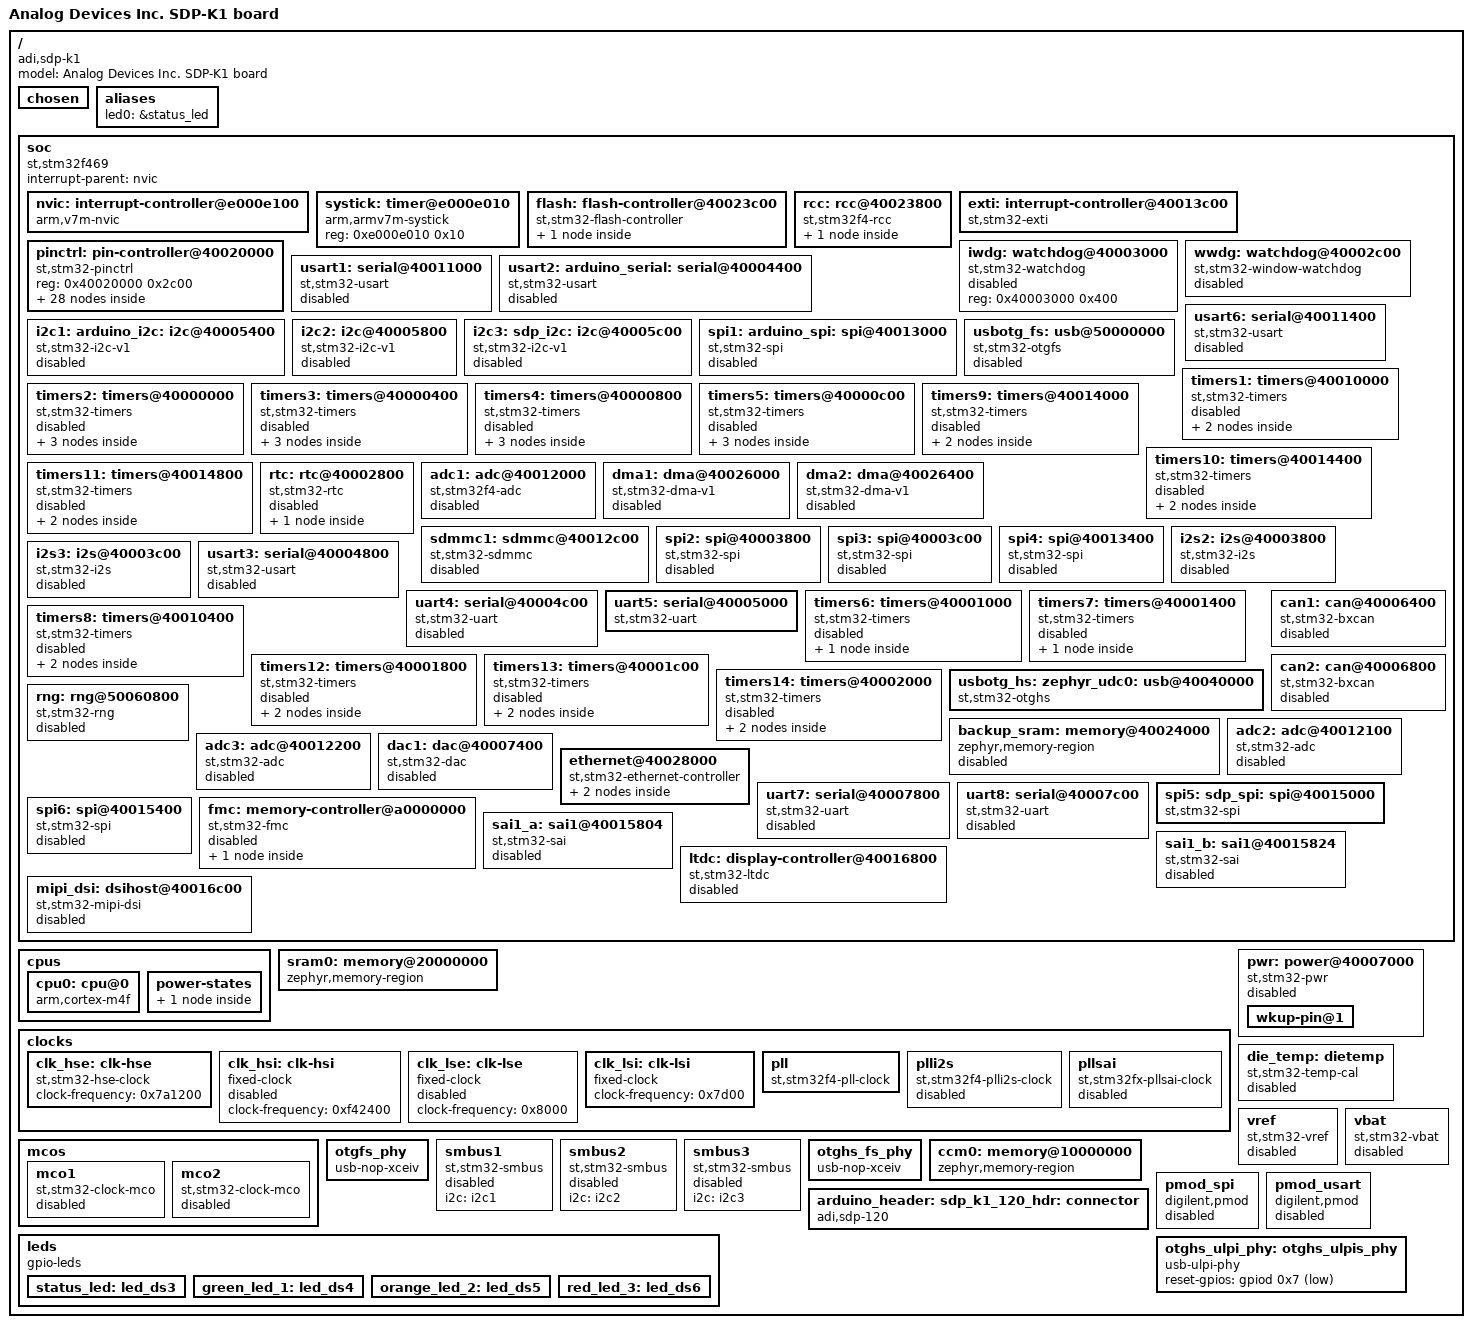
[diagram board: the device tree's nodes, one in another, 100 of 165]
/dts-v1/;

/* node '/' defined in zephyr/dts/common/skeleton.dtsi:9 */
/ {
	#address-cells = < 0x1 >;                   /* in zephyr/dts/common/skeleton.dtsi:10 */
	#size-cells = < 0x1 >;                      /* in zephyr/dts/common/skeleton.dtsi:11 */
	model = "Analog Devices Inc. SDP-K1 board"; /* in zephyr/boards/adi/sdp_k1/adi_sdp_k1.dts:14 */
	compatible = "adi,sdp-k1";                  /* in zephyr/boards/adi/sdp_k1/adi_sdp_k1.dts:15 */

	/* node '/chosen' defined in zephyr/dts/common/skeleton.dtsi:13 */
	chosen {
		zephyr,flash-controller = &flash;  /* in zephyr/dts/arm/st/f4/stm32f4.dtsi:27 */
		zephyr,cortex-m-idle-timer = &rtc; /* in zephyr/dts/arm/st/f4/stm32f4.dtsi:28 */
		zephyr,entropy = &rng;             /* in zephyr/dts/arm/st/f4/stm32f405.dtsi:13 */
		zephyr,console = &uart5;           /* in zephyr/boards/adi/sdp_k1/adi_sdp_k1.dts:18 */
		zephyr,shell-uart = &uart5;        /* in zephyr/boards/adi/sdp_k1/adi_sdp_k1.dts:19 */
		zephyr,sram = &sram0;              /* in zephyr/boards/adi/sdp_k1/adi_sdp_k1.dts:20 */
		zephyr,flash = &flash0;            /* in zephyr/boards/adi/sdp_k1/adi_sdp_k1.dts:21 */
		zephyr,ccm = &ccm0;                /* in zephyr/boards/adi/sdp_k1/adi_sdp_k1.dts:22 */
	};

	/* node '/aliases' defined in zephyr/dts/common/skeleton.dtsi:15 */
	aliases {
		led0 = &status_led; /* in zephyr/boards/adi/sdp_k1/adi_sdp_k1.dts:56 */
	};

	/* node '/soc' defined in zephyr/dts/arm/armv7-m.dtsi:6 */
	soc {
		#address-cells = < 0x1 >;     /* in zephyr/dts/arm/armv7-m.dtsi:7 */
		#size-cells = < 0x1 >;        /* in zephyr/dts/arm/armv7-m.dtsi:8 */
		interrupt-parent = < &nvic >; /* in zephyr/dts/arm/armv7-m.dtsi:10 */
		ranges;                       /* in zephyr/dts/arm/armv7-m.dtsi:11 */
		compatible = "st,stm32f469",
		             "st,stm32f4",
		             "simple-bus";    /* in zephyr/dts/arm/st/f4/stm32f469.dtsi:12 */

		/* node '/soc/interrupt-controller@e000e100' defined in zephyr/dts/arm/armv7-m.dtsi:13 */
		nvic: interrupt-controller@e000e100 {
			#address-cells = < 0x1 >;            /* in zephyr/dts/arm/armv7-m.dtsi:14 */
			compatible = "arm,v7m-nvic";         /* in zephyr/dts/arm/armv7-m.dtsi:15 */
			reg = < 0xe000e100 0xc00 >;          /* in zephyr/dts/arm/armv7-m.dtsi:16 */
			interrupt-controller;                /* in zephyr/dts/arm/armv7-m.dtsi:17 */
			#interrupt-cells = < 0x2 >;          /* in zephyr/dts/arm/armv7-m.dtsi:18 */
			arm,num-irq-priority-bits = < 0x4 >; /* in zephyr/dts/arm/st/f4/stm32f4.dtsi:676 */
			phandle = < 0x1 >;                   /* in zephyr/dts/arm/armv7-m.dtsi:10 */
		};

		/* node '/soc/timer@e000e010' defined in zephyr/dts/arm/armv7-m.dtsi:21 */
		systick: timer@e000e010 {
			compatible = "arm,armv7m-systick"; /* in zephyr/dts/arm/armv7-m.dtsi:22 */
			reg = < 0xe000e010 0x10 >;         /* in zephyr/dts/arm/armv7-m.dtsi:23 */
		};

		/* node '/soc/flash-controller@40023c00' defined in zephyr/dts/arm/st/f4/stm32f4.dtsi:111 */
		flash: flash-controller@40023c00 {
			compatible = "st,stm32-flash-controller",
			             "st,stm32f4-flash-controller"; /* in zephyr/dts/arm/st/f4/stm32f4.dtsi:112 */
			reg = < 0x40023c00 0x400 >;                 /* in zephyr/dts/arm/st/f4/stm32f4.dtsi:113 */
			interrupts = < 0x4 0x0 >;                   /* in zephyr/dts/arm/st/f4/stm32f4.dtsi:114 */
			#address-cells = < 0x1 >;                   /* in zephyr/dts/arm/st/f4/stm32f4.dtsi:116 */
			#size-cells = < 0x1 >;                      /* in zephyr/dts/arm/st/f4/stm32f4.dtsi:117 */

			/* node '/soc/flash-controller@40023c00/flash@8000000' defined in zephyr/dts/arm/st/f4/stm32f4.dtsi:119 */
			flash0: flash@8000000 {
				compatible = "st,stm32f4-nv-flash",
				             "st,stm32-nv-flash",
				             "soc-nv-flash";        /* in zephyr/dts/arm/st/f4/stm32f4.dtsi:120 */
				write-block-size = < 0x1 >;         /* in zephyr/dts/arm/st/f4/stm32f4.dtsi:123 */
				max-erase-time = < 0xfa0 >;         /* in zephyr/dts/arm/st/f4/stm32f4.dtsi:125 */
				reg = < 0x8000000 0x200000 >;       /* in zephyr/dts/arm/st/f4/stm32f469Xi.dtsi:23 */
			};
		};

		/* node '/soc/rcc@40023800' defined in zephyr/dts/arm/st/f4/stm32f4.dtsi:129 */
		rcc: rcc@40023800 {
			#clock-cells = < 0x2 >;          /* in zephyr/dts/arm/st/f4/stm32f4.dtsi:131 */
			reg = < 0x40023800 0x400 >;      /* in zephyr/dts/arm/st/f4/stm32f4.dtsi:132 */
			compatible = "st,stm32f4-rcc";   /* in zephyr/dts/arm/st/f4/stm32f427.dtsi:25 */
			clocks = < &pll >;               /* in zephyr/boards/adi/sdp_k1/adi_sdp_k1.dts:79 */
			clock-frequency = < 0xa037a00 >; /* in zephyr/boards/adi/sdp_k1/adi_sdp_k1.dts:80 */
			ahb-prescaler = < 0x1 >;         /* in zephyr/boards/adi/sdp_k1/adi_sdp_k1.dts:81 */
			apb1-prescaler = < 0x4 >;        /* in zephyr/boards/adi/sdp_k1/adi_sdp_k1.dts:82 */
			apb2-prescaler = < 0x2 >;        /* in zephyr/boards/adi/sdp_k1/adi_sdp_k1.dts:83 */
			phandle = < 0x3 >;               /* in zephyr/dts/arm/st/f4/stm32f4.dtsi:146 */

			/* node '/soc/rcc@40023800/reset-controller' defined in zephyr/dts/arm/st/f4/stm32f4.dtsi:134 */
			rctl: reset-controller {
				compatible = "st,stm32-rcc-rctl"; /* in zephyr/dts/arm/st/f4/stm32f4.dtsi:135 */
				#reset-cells = < 0x1 >;           /* in zephyr/dts/arm/st/f4/stm32f4.dtsi:136 */
				phandle = < 0x4 >;                /* in zephyr/dts/arm/st/f4/stm32f4.dtsi:245 */
			};
		};

		/* node '/soc/interrupt-controller@40013c00' defined in zephyr/dts/arm/st/f4/stm32f4.dtsi:140 */
		exti: interrupt-controller@40013c00 {
			compatible = "st,stm32-exti";  /* in zephyr/dts/arm/st/f4/stm32f4.dtsi:141 */
			interrupt-controller;          /* in zephyr/dts/arm/st/f4/stm32f4.dtsi:142 */
			#interrupt-cells = < 0x1 >;    /* in zephyr/dts/arm/st/f4/stm32f4.dtsi:143 */
			#address-cells = < 0x0 >;      /* in zephyr/dts/arm/st/f4/stm32f4.dtsi:144 */
			reg = < 0x40013c00 0x400 >;    /* in zephyr/dts/arm/st/f4/stm32f4.dtsi:145 */
			clocks = < &rcc 0x44 0x4000 >; /* in zephyr/dts/arm/st/f4/stm32f4.dtsi:146 */
			num-lines = < 0x20 >;          /* in zephyr/dts/arm/st/f4/stm32f4.dtsi:147 */
			interrupts = < 0x6 0x0 >,
			             < 0x7 0x0 >,
			             < 0x8 0x0 >,
			             < 0x9 0x0 >,
			             < 0xa 0x0 >,
			             < 0x17 0x0 >,
			             < 0x28 0x0 >;     /* in zephyr/dts/arm/st/f4/stm32f4.dtsi:148 */
			interrupt-names = "line0",
			                  "line1",
			                  "line2",
			                  "line3",
			                  "line4",
			                  "line5-9",
			                  "line10-15"; /* in zephyr/dts/arm/st/f4/stm32f4.dtsi:150 */
			line-ranges = < 0x0 0x1 >,
			              < 0x1 0x1 >,
			              < 0x2 0x1 >,
			              < 0x3 0x1 >,
			              < 0x4 0x1 >,
			              < 0x5 0x5 >,
			              < 0xa 0x6 >;     /* in zephyr/dts/arm/st/f4/stm32f4.dtsi:152 */
		};

		/* node '/soc/pin-controller@40020000' defined in zephyr/dts/arm/st/f4/stm32f4.dtsi:156 */
		pinctrl: pin-controller@40020000 {
			compatible = "st,stm32-pinctrl"; /* in zephyr/dts/arm/st/f4/stm32f4.dtsi:157 */
			#address-cells = < 0x1 >;        /* in zephyr/dts/arm/st/f4/stm32f4.dtsi:158 */
			#size-cells = < 0x1 >;           /* in zephyr/dts/arm/st/f4/stm32f4.dtsi:159 */
			reg = < 0x40020000 0x2c00 >;     /* in zephyr/dts/arm/st/f4/stm32f427.dtsi:29 */

			/* node '/soc/pin-controller@40020000/gpio@40020000' defined in zephyr/dts/arm/st/f4/stm32f4.dtsi:162 */
			gpioa: gpio@40020000 {
				compatible = "st,stm32-gpio"; /* in zephyr/dts/arm/st/f4/stm32f4.dtsi:163 */
				gpio-controller;              /* in zephyr/dts/arm/st/f4/stm32f4.dtsi:164 */
				#gpio-cells = < 0x2 >;        /* in zephyr/dts/arm/st/f4/stm32f4.dtsi:165 */
				reg = < 0x40020000 0x400 >;   /* in zephyr/dts/arm/st/f4/stm32f4.dtsi:166 */
				clocks = < &rcc 0x30 0x1 >;   /* in zephyr/dts/arm/st/f4/stm32f4.dtsi:167 */
				phandle = < 0x1d >;           /* in zephyr/dts/arm/st/f4/stm32f4.dtsi:615 */
			};

			/* node '/soc/pin-controller@40020000/gpio@40020400' defined in zephyr/dts/arm/st/f4/stm32f4.dtsi:170 */
			gpiob: gpio@40020400 {
				compatible = "st,stm32-gpio"; /* in zephyr/dts/arm/st/f4/stm32f4.dtsi:171 */
				gpio-controller;              /* in zephyr/dts/arm/st/f4/stm32f4.dtsi:172 */
				#gpio-cells = < 0x2 >;        /* in zephyr/dts/arm/st/f4/stm32f4.dtsi:173 */
				reg = < 0x40020400 0x400 >;   /* in zephyr/dts/arm/st/f4/stm32f4.dtsi:174 */
				clocks = < &rcc 0x30 0x2 >;   /* in zephyr/dts/arm/st/f4/stm32f4.dtsi:175 */
				phandle = < 0x26 >;           /* in zephyr/boards/adi/sdp_k1/adi_sdp_120pin_connector.dtsi:16 */
			};

			/* node '/soc/pin-controller@40020000/gpio@40020800' defined in zephyr/dts/arm/st/f4/stm32f4.dtsi:178 */
			gpioc: gpio@40020800 {
				compatible = "st,stm32-gpio"; /* in zephyr/dts/arm/st/f4/stm32f4.dtsi:179 */
				gpio-controller;              /* in zephyr/dts/arm/st/f4/stm32f4.dtsi:180 */
				#gpio-cells = < 0x2 >;        /* in zephyr/dts/arm/st/f4/stm32f4.dtsi:181 */
				reg = < 0x40020800 0x400 >;   /* in zephyr/dts/arm/st/f4/stm32f4.dtsi:182 */
				clocks = < &rcc 0x30 0x4 >;   /* in zephyr/dts/arm/st/f4/stm32f4.dtsi:183 */
				phandle = < 0x24 >;           /* in zephyr/boards/adi/sdp_k1/adi_sdp_120pin_connector.dtsi:16 */
			};

			/* node '/soc/pin-controller@40020000/gpio@40020c00' defined in zephyr/dts/arm/st/f4/stm32f4.dtsi:186 */
			gpiod: gpio@40020c00 {
				compatible = "st,stm32-gpio"; /* in zephyr/dts/arm/st/f4/stm32f4.dtsi:187 */
				gpio-controller;              /* in zephyr/dts/arm/st/f4/stm32f4.dtsi:188 */
				#gpio-cells = < 0x2 >;        /* in zephyr/dts/arm/st/f4/stm32f4.dtsi:189 */
				reg = < 0x40020c00 0x400 >;   /* in zephyr/dts/arm/st/f4/stm32f4.dtsi:190 */
				clocks = < &rcc 0x30 0x8 >;   /* in zephyr/dts/arm/st/f4/stm32f4.dtsi:191 */
				phandle = < 0x23 >;           /* in zephyr/boards/adi/sdp_k1/adi_sdp_120pin_connector.dtsi:16 */
			};

			/* node '/soc/pin-controller@40020000/gpio@40021000' defined in zephyr/dts/arm/st/f4/stm32f4.dtsi:194 */
			gpioe: gpio@40021000 {
				compatible = "st,stm32-gpio"; /* in zephyr/dts/arm/st/f4/stm32f4.dtsi:195 */
				gpio-controller;              /* in zephyr/dts/arm/st/f4/stm32f4.dtsi:196 */
				#gpio-cells = < 0x2 >;        /* in zephyr/dts/arm/st/f4/stm32f4.dtsi:197 */
				reg = < 0x40021000 0x400 >;   /* in zephyr/dts/arm/st/f4/stm32f4.dtsi:198 */
				clocks = < &rcc 0x30 0x10 >;  /* in zephyr/dts/arm/st/f4/stm32f4.dtsi:199 */
				phandle = < 0x27 >;           /* in zephyr/boards/adi/sdp_k1/adi_sdp_120pin_connector.dtsi:16 */
			};

			/* node '/soc/pin-controller@40020000/gpio@40021400' defined in zephyr/dts/arm/st/f4/stm32f4.dtsi:202 */
			gpiof: gpio@40021400 {
				compatible = "st,stm32-gpio"; /* in zephyr/dts/arm/st/f4/stm32f405.dtsi:27 */
				gpio-controller;              /* in zephyr/dts/arm/st/f4/stm32f405.dtsi:28 */
				#gpio-cells = < 0x2 >;        /* in zephyr/dts/arm/st/f4/stm32f405.dtsi:29 */
				reg = < 0x40021400 0x400 >;   /* in zephyr/dts/arm/st/f4/stm32f405.dtsi:30 */
				clocks = < &rcc 0x30 0x20 >;  /* in zephyr/dts/arm/st/f4/stm32f405.dtsi:31 */
				phandle = < 0x22 >;           /* in zephyr/boards/adi/sdp_k1/adi_sdp_120pin_connector.dtsi:16 */
			};

			/* node '/soc/pin-controller@40020000/gpio@40021800' defined in zephyr/dts/arm/st/f4/stm32f4.dtsi:210 */
			gpiog: gpio@40021800 {
				compatible = "st,stm32-gpio"; /* in zephyr/dts/arm/st/f4/stm32f405.dtsi:35 */
				gpio-controller;              /* in zephyr/dts/arm/st/f4/stm32f405.dtsi:36 */
				#gpio-cells = < 0x2 >;        /* in zephyr/dts/arm/st/f4/stm32f405.dtsi:37 */
				reg = < 0x40021800 0x400 >;   /* in zephyr/dts/arm/st/f4/stm32f405.dtsi:38 */
				clocks = < &rcc 0x30 0x40 >;  /* in zephyr/dts/arm/st/f4/stm32f405.dtsi:39 */
				phandle = < 0x29 >;           /* in zephyr/boards/adi/sdp_k1/adi_sdp_120pin_connector.dtsi:16 */
			};

			/* node '/soc/pin-controller@40020000/gpio@40021c00' defined in zephyr/dts/arm/st/f4/stm32f4.dtsi:218 */
			gpioh: gpio@40021c00 {
				compatible = "st,stm32-gpio"; /* in zephyr/dts/arm/st/f4/stm32f4.dtsi:219 */
				gpio-controller;              /* in zephyr/dts/arm/st/f4/stm32f4.dtsi:220 */
				#gpio-cells = < 0x2 >;        /* in zephyr/dts/arm/st/f4/stm32f4.dtsi:221 */
				reg = < 0x40021c00 0x400 >;   /* in zephyr/dts/arm/st/f4/stm32f4.dtsi:222 */
				clocks = < &rcc 0x30 0x80 >;  /* in zephyr/dts/arm/st/f4/stm32f4.dtsi:223 */
				phandle = < 0x28 >;           /* in zephyr/boards/adi/sdp_k1/adi_sdp_120pin_connector.dtsi:16 */
			};

			/* node '/soc/pin-controller@40020000/gpio@40022000' defined in zephyr/dts/arm/st/f4/stm32f405.dtsi:42 */
			gpioi: gpio@40022000 {
				compatible = "st,stm32-gpio"; /* in zephyr/dts/arm/st/f4/stm32f405.dtsi:43 */
				gpio-controller;              /* in zephyr/dts/arm/st/f4/stm32f405.dtsi:44 */
				#gpio-cells = < 0x2 >;        /* in zephyr/dts/arm/st/f4/stm32f405.dtsi:45 */
				reg = < 0x40022000 0x400 >;   /* in zephyr/dts/arm/st/f4/stm32f405.dtsi:46 */
				clocks = < &rcc 0x30 0x100 >; /* in zephyr/dts/arm/st/f4/stm32f405.dtsi:47 */
			};

			/* node '/soc/pin-controller@40020000/gpio@40022400' defined in zephyr/dts/arm/st/f4/stm32f427.dtsi:31 */
			gpioj: gpio@40022400 {
				compatible = "st,stm32-gpio"; /* in zephyr/dts/arm/st/f4/stm32f427.dtsi:32 */
				gpio-controller;              /* in zephyr/dts/arm/st/f4/stm32f427.dtsi:33 */
				#gpio-cells = < 0x2 >;        /* in zephyr/dts/arm/st/f4/stm32f427.dtsi:34 */
				reg = < 0x40022400 0x400 >;   /* in zephyr/dts/arm/st/f4/stm32f427.dtsi:35 */
				clocks = < &rcc 0x30 0x200 >; /* in zephyr/dts/arm/st/f4/stm32f427.dtsi:36 */
				phandle = < 0x25 >;           /* in zephyr/boards/adi/sdp_k1/adi_sdp_120pin_connector.dtsi:16 */
			};

			/* node '/soc/pin-controller@40020000/gpio@40022800' defined in zephyr/dts/arm/st/f4/stm32f427.dtsi:39 */
			gpiok: gpio@40022800 {
				compatible = "st,stm32-gpio"; /* in zephyr/dts/arm/st/f4/stm32f427.dtsi:40 */
				gpio-controller;              /* in zephyr/dts/arm/st/f4/stm32f427.dtsi:41 */
				#gpio-cells = < 0x2 >;        /* in zephyr/dts/arm/st/f4/stm32f427.dtsi:42 */
				reg = < 0x40022800 0x400 >;   /* in zephyr/dts/arm/st/f4/stm32f427.dtsi:43 */
				clocks = < &rcc 0x30 0x400 >; /* in zephyr/dts/arm/st/f4/stm32f427.dtsi:44 */
				phandle = < 0x2a >;           /* in zephyr/boards/adi/sdp_k1/adi_sdp_k1.dts:29 */
			};

			/* node '/soc/pin-controller@40020000/spi5_miso_pf8' defined in modules/hal/stm32/dts/st/f4/stm32f469nihx-pinctrl.dtsi:2758 */
			spi5_miso_pf8: spi5_miso_pf8 {
				pinmux = < 0xb05 >; /* in modules/hal/stm32/dts/st/f4/stm32f469nihx-pinctrl.dtsi:2759 */
				bias-pull-down;     /* in modules/hal/stm32/dts/st/f4/stm32f469nihx-pinctrl.dtsi:2760 */
				phandle = < 0x17 >; /* in zephyr/boards/adi/sdp_k1/adi_sdp_120pin_connector.dtsi:106 */
			};

			/* node '/soc/pin-controller@40020000/spi5_mosi_pf9' defined in modules/hal/stm32/dts/st/f4/stm32f469nihx-pinctrl.dtsi:2830 */
			spi5_mosi_pf9: spi5_mosi_pf9 {
				pinmux = < 0xb25 >; /* in modules/hal/stm32/dts/st/f4/stm32f469nihx-pinctrl.dtsi:2831 */
				bias-pull-down;     /* in modules/hal/stm32/dts/st/f4/stm32f469nihx-pinctrl.dtsi:2832 */
				phandle = < 0x18 >; /* in zephyr/boards/adi/sdp_k1/adi_sdp_120pin_connector.dtsi:106 */
			};

			/* node '/soc/pin-controller@40020000/spi5_sck_ph6' defined in modules/hal/stm32/dts/st/f4/stm32f469nihx-pinctrl.dtsi:2981 */
			spi5_sck_ph6: spi5_sck_ph6 {
				pinmux = < 0xec5 >;            /* in modules/hal/stm32/dts/st/f4/stm32f469nihx-pinctrl.dtsi:2982 */
				bias-pull-down;                /* in modules/hal/stm32/dts/st/f4/stm32f469nihx-pinctrl.dtsi:2983 */
				slew-rate = "very-high-speed"; /* in modules/hal/stm32/dts/st/f4/stm32f469nihx-pinctrl.dtsi:2984 */
				phandle = < 0x16 >;            /* in zephyr/boards/adi/sdp_k1/adi_sdp_120pin_connector.dtsi:106 */
			};

			/* node '/soc/pin-controller@40020000/uart5_rx_pd2' defined in modules/hal/stm32/dts/st/f4/stm32f469nihx-pinctrl.dtsi:3469 */
			uart5_rx_pd2: uart5_rx_pd2 {
				pinmux = < 0x648 >; /* in modules/hal/stm32/dts/st/f4/stm32f469nihx-pinctrl.dtsi:3470 */
				phandle = < 0x8 >;  /* in zephyr/boards/adi/sdp_k1/adi_sdp_k1.dts:87 */
			};

			/* node '/soc/pin-controller@40020000/uart5_tx_pc12' defined in modules/hal/stm32/dts/st/f4/stm32f469nihx-pinctrl.dtsi:3540 */
			uart5_tx_pc12: uart5_tx_pc12 {
				pinmux = < 0x588 >; /* in modules/hal/stm32/dts/st/f4/stm32f469nihx-pinctrl.dtsi:3541 */
				bias-pull-up;       /* in modules/hal/stm32/dts/st/f4/stm32f469nihx-pinctrl.dtsi:3542 */
				phandle = < 0x7 >;  /* in zephyr/boards/adi/sdp_k1/adi_sdp_k1.dts:87 */
			};

			/* node '/soc/pin-controller@40020000/usb_otg_hs_ulpi_d0_pa3' defined in modules/hal/stm32/dts/st/f4/stm32f469nihx-pinctrl.dtsi:3616 */
			usb_otg_hs_ulpi_d0_pa3: usb_otg_hs_ulpi_d0_pa3 {
				pinmux = < 0x6a >;        /* in modules/hal/stm32/dts/st/f4/stm32f469nihx-pinctrl.dtsi:3617 */
				slew-rate = "high-speed"; /* in modules/hal/stm32/dts/st/f4/stm32f469nihx-pinctrl.dtsi:3618 */
				phandle = < 0xa >;        /* in zephyr/boards/adi/sdp_k1/adi_sdp_k1.dts:94 */
			};

			/* node '/soc/pin-controller@40020000/usb_otg_hs_ulpi_ck_pa5' defined in modules/hal/stm32/dts/st/f4/stm32f469nihx-pinctrl.dtsi:3621 */
			usb_otg_hs_ulpi_ck_pa5: usb_otg_hs_ulpi_ck_pa5 {
				pinmux = < 0xaa >;        /* in modules/hal/stm32/dts/st/f4/stm32f469nihx-pinctrl.dtsi:3622 */
				slew-rate = "high-speed"; /* in modules/hal/stm32/dts/st/f4/stm32f469nihx-pinctrl.dtsi:3623 */
				phandle = < 0x9 >;        /* in zephyr/boards/adi/sdp_k1/adi_sdp_k1.dts:94 */
			};

			/* node '/soc/pin-controller@40020000/usb_otg_hs_ulpi_d1_pb0' defined in modules/hal/stm32/dts/st/f4/stm32f469nihx-pinctrl.dtsi:3626 */
			usb_otg_hs_ulpi_d1_pb0: usb_otg_hs_ulpi_d1_pb0 {
				pinmux = < 0x20a >;       /* in modules/hal/stm32/dts/st/f4/stm32f469nihx-pinctrl.dtsi:3627 */
				slew-rate = "high-speed"; /* in modules/hal/stm32/dts/st/f4/stm32f469nihx-pinctrl.dtsi:3628 */
				phandle = < 0xb >;        /* in zephyr/boards/adi/sdp_k1/adi_sdp_k1.dts:94 */
			};

			/* node '/soc/pin-controller@40020000/usb_otg_hs_ulpi_d2_pb1' defined in modules/hal/stm32/dts/st/f4/stm32f469nihx-pinctrl.dtsi:3631 */
			usb_otg_hs_ulpi_d2_pb1: usb_otg_hs_ulpi_d2_pb1 {
				pinmux = < 0x22a >;       /* in modules/hal/stm32/dts/st/f4/stm32f469nihx-pinctrl.dtsi:3632 */
				slew-rate = "high-speed"; /* in modules/hal/stm32/dts/st/f4/stm32f469nihx-pinctrl.dtsi:3633 */
				phandle = < 0xc >;        /* in zephyr/boards/adi/sdp_k1/adi_sdp_k1.dts:94 */
			};

			/* node '/soc/pin-controller@40020000/usb_otg_hs_ulpi_d7_pb5' defined in modules/hal/stm32/dts/st/f4/stm32f469nihx-pinctrl.dtsi:3636 */
			usb_otg_hs_ulpi_d7_pb5: usb_otg_hs_ulpi_d7_pb5 {
				pinmux = < 0x2aa >;       /* in modules/hal/stm32/dts/st/f4/stm32f469nihx-pinctrl.dtsi:3637 */
				slew-rate = "high-speed"; /* in modules/hal/stm32/dts/st/f4/stm32f469nihx-pinctrl.dtsi:3638 */
				phandle = < 0x11 >;       /* in zephyr/boards/adi/sdp_k1/adi_sdp_k1.dts:94 */
			};

			/* node '/soc/pin-controller@40020000/usb_otg_hs_ulpi_d3_pb10' defined in modules/hal/stm32/dts/st/f4/stm32f469nihx-pinctrl.dtsi:3641 */
			usb_otg_hs_ulpi_d3_pb10: usb_otg_hs_ulpi_d3_pb10 {
				pinmux = < 0x34a >;       /* in modules/hal/stm32/dts/st/f4/stm32f469nihx-pinctrl.dtsi:3642 */
				slew-rate = "high-speed"; /* in modules/hal/stm32/dts/st/f4/stm32f469nihx-pinctrl.dtsi:3643 */
				phandle = < 0xd >;        /* in zephyr/boards/adi/sdp_k1/adi_sdp_k1.dts:94 */
			};

			/* node '/soc/pin-controller@40020000/usb_otg_hs_ulpi_d4_pb11' defined in modules/hal/stm32/dts/st/f4/stm32f469nihx-pinctrl.dtsi:3646 */
			usb_otg_hs_ulpi_d4_pb11: usb_otg_hs_ulpi_d4_pb11 {
				pinmux = < 0x36a >;       /* in modules/hal/stm32/dts/st/f4/stm32f469nihx-pinctrl.dtsi:3647 */
				slew-rate = "high-speed"; /* in modules/hal/stm32/dts/st/f4/stm32f469nihx-pinctrl.dtsi:3648 */
				phandle = < 0xe >;        /* in zephyr/boards/adi/sdp_k1/adi_sdp_k1.dts:94 */
			};

			/* node '/soc/pin-controller@40020000/usb_otg_hs_ulpi_d5_pb12' defined in modules/hal/stm32/dts/st/f4/stm32f469nihx-pinctrl.dtsi:3651 */
			usb_otg_hs_ulpi_d5_pb12: usb_otg_hs_ulpi_d5_pb12 {
				pinmux = < 0x38a >;       /* in modules/hal/stm32/dts/st/f4/stm32f469nihx-pinctrl.dtsi:3652 */
				slew-rate = "high-speed"; /* in modules/hal/stm32/dts/st/f4/stm32f469nihx-pinctrl.dtsi:3653 */
				phandle = < 0xf >;        /* in zephyr/boards/adi/sdp_k1/adi_sdp_k1.dts:94 */
			};

			/* node '/soc/pin-controller@40020000/usb_otg_hs_ulpi_d6_pb13' defined in modules/hal/stm32/dts/st/f4/stm32f469nihx-pinctrl.dtsi:3656 */
			usb_otg_hs_ulpi_d6_pb13: usb_otg_hs_ulpi_d6_pb13 {
				pinmux = < 0x3aa >;       /* in modules/hal/stm32/dts/st/f4/stm32f469nihx-pinctrl.dtsi:3657 */
				slew-rate = "high-speed"; /* in modules/hal/stm32/dts/st/f4/stm32f469nihx-pinctrl.dtsi:3658 */
				phandle = < 0x10 >;       /* in zephyr/boards/adi/sdp_k1/adi_sdp_k1.dts:94 */
			};

			/* node '/soc/pin-controller@40020000/usb_otg_hs_ulpi_stp_pc0' defined in modules/hal/stm32/dts/st/f4/stm32f469nihx-pinctrl.dtsi:3661 */
			usb_otg_hs_ulpi_stp_pc0: usb_otg_hs_ulpi_stp_pc0 {
				pinmux = < 0x40a >;       /* in modules/hal/stm32/dts/st/f4/stm32f469nihx-pinctrl.dtsi:3662 */
				slew-rate = "high-speed"; /* in modules/hal/stm32/dts/st/f4/stm32f469nihx-pinctrl.dtsi:3663 */
				phandle = < 0x12 >;       /* in zephyr/boards/adi/sdp_k1/adi_sdp_k1.dts:94 */
			};

			/* node '/soc/pin-controller@40020000/usb_otg_hs_ulpi_dir_pc2' defined in modules/hal/stm32/dts/st/f4/stm32f469nihx-pinctrl.dtsi:3666 */
			usb_otg_hs_ulpi_dir_pc2: usb_otg_hs_ulpi_dir_pc2 {
				pinmux = < 0x44a >;       /* in modules/hal/stm32/dts/st/f4/stm32f469nihx-pinctrl.dtsi:3667 */
				slew-rate = "high-speed"; /* in modules/hal/stm32/dts/st/f4/stm32f469nihx-pinctrl.dtsi:3668 */
				phandle = < 0x13 >;       /* in zephyr/boards/adi/sdp_k1/adi_sdp_k1.dts:94 */
			};

			/* node '/soc/pin-controller@40020000/usb_otg_hs_ulpi_nxt_pc3' defined in modules/hal/stm32/dts/st/f4/stm32f469nihx-pinctrl.dtsi:3671 */
			usb_otg_hs_ulpi_nxt_pc3: usb_otg_hs_ulpi_nxt_pc3 {
				pinmux = < 0x46a >;       /* in modules/hal/stm32/dts/st/f4/stm32f469nihx-pinctrl.dtsi:3672 */
				slew-rate = "high-speed"; /* in modules/hal/stm32/dts/st/f4/stm32f469nihx-pinctrl.dtsi:3673 */
				phandle = < 0x14 >;       /* in zephyr/boards/adi/sdp_k1/adi_sdp_k1.dts:94 */
			};
		};

		/* node '/soc/watchdog@40003000' defined in zephyr/dts/arm/st/f4/stm32f4.dtsi:227 */
		iwdg: watchdog@40003000 {
			compatible = "st,stm32-watchdog"; /* in zephyr/dts/arm/st/f4/stm32f4.dtsi:228 */
			reg = < 0x40003000 0x400 >;       /* in zephyr/dts/arm/st/f4/stm32f4.dtsi:229 */
			status = "disabled";              /* in zephyr/dts/arm/st/f4/stm32f4.dtsi:230 */
		};

		/* node '/soc/watchdog@40002c00' defined in zephyr/dts/arm/st/f4/stm32f4.dtsi:233 */
		wwdg: watchdog@40002c00 {
			compatible = "st,stm32-window-watchdog"; /* in zephyr/dts/arm/st/f4/stm32f4.dtsi:234 */
			reg = < 0x40002c00 0x400 >;              /* in zephyr/dts/arm/st/f4/stm32f4.dtsi:235 */
			clocks = < &rcc 0x40 0x800 >;            /* in zephyr/dts/arm/st/f4/stm32f4.dtsi:236 */
			interrupts = < 0x0 0x7 >;                /* in zephyr/dts/arm/st/f4/stm32f4.dtsi:237 */
			status = "disabled";                     /* in zephyr/dts/arm/st/f4/stm32f4.dtsi:238 */
		};

		/* node '/soc/serial@40011000' defined in zephyr/dts/arm/st/f4/stm32f4.dtsi:241 */
		usart1: serial@40011000 {
			compatible = "st,stm32-usart",
			             "st,stm32-uart";  /* in zephyr/dts/arm/st/f4/stm32f4.dtsi:242 */
			reg = < 0x40011000 0x400 >;    /* in zephyr/dts/arm/st/f4/stm32f4.dtsi:243 */
			clocks = < &rcc 0x44 0x10 >;   /* in zephyr/dts/arm/st/f4/stm32f4.dtsi:244 */
			resets = < &rctl 0x484 >;      /* in zephyr/dts/arm/st/f4/stm32f4.dtsi:245 */
			interrupts = < 0x25 0x0 >;     /* in zephyr/dts/arm/st/f4/stm32f4.dtsi:246 */
			status = "disabled";           /* in zephyr/dts/arm/st/f4/stm32f4.dtsi:247 */
		};

		/* node '/soc/serial@40004400' defined in zephyr/dts/arm/st/f4/stm32f4.dtsi:250 */
		usart2: arduino_serial: sdp_serial: serial@40004400 {
			compatible = "st,stm32-usart",
			             "st,stm32-uart";   /* in zephyr/dts/arm/st/f4/stm32f4.dtsi:251 */
			reg = < 0x40004400 0x400 >;     /* in zephyr/dts/arm/st/f4/stm32f4.dtsi:252 */
			clocks = < &rcc 0x40 0x20000 >; /* in zephyr/dts/arm/st/f4/stm32f4.dtsi:253 */
			resets = < &rctl 0x411 >;       /* in zephyr/dts/arm/st/f4/stm32f4.dtsi:254 */
			interrupts = < 0x26 0x0 >;      /* in zephyr/dts/arm/st/f4/stm32f4.dtsi:255 */
			status = "disabled";            /* in zephyr/dts/arm/st/f4/stm32f4.dtsi:256 */
		};

		/* node '/soc/serial@40011400' defined in zephyr/dts/arm/st/f4/stm32f4.dtsi:259 */
		usart6: serial@40011400 {
			compatible = "st,stm32-usart",
			             "st,stm32-uart";  /* in zephyr/dts/arm/st/f4/stm32f4.dtsi:260 */
			reg = < 0x40011400 0x400 >;    /* in zephyr/dts/arm/st/f4/stm32f4.dtsi:261 */
			clocks = < &rcc 0x44 0x20 >;   /* in zephyr/dts/arm/st/f4/stm32f4.dtsi:262 */
			resets = < &rctl 0x485 >;      /* in zephyr/dts/arm/st/f4/stm32f4.dtsi:263 */
			interrupts = < 0x47 0x0 >;     /* in zephyr/dts/arm/st/f4/stm32f4.dtsi:264 */
			status = "disabled";           /* in zephyr/dts/arm/st/f4/stm32f4.dtsi:265 */
		};

		/* node '/soc/i2c@40005400' defined in zephyr/dts/arm/st/f4/stm32f4.dtsi:268 */
		i2c1: arduino_i2c: i2c@40005400 {
			compatible = "st,stm32-i2c-v1";  /* in zephyr/dts/arm/st/f4/stm32f4.dtsi:269 */
			clock-frequency = < 0x186a0 >;   /* in zephyr/dts/arm/st/f4/stm32f4.dtsi:270 */
			#address-cells = < 0x1 >;        /* in zephyr/dts/arm/st/f4/stm32f4.dtsi:271 */
			#size-cells = < 0x0 >;           /* in zephyr/dts/arm/st/f4/stm32f4.dtsi:272 */
			reg = < 0x40005400 0x400 >;      /* in zephyr/dts/arm/st/f4/stm32f4.dtsi:273 */
			clocks = < &rcc 0x40 0x200000 >; /* in zephyr/dts/arm/st/f4/stm32f4.dtsi:274 */
			interrupts = < 0x1f 0x0 >,
			             < 0x20 0x0 >;       /* in zephyr/dts/arm/st/f4/stm32f4.dtsi:275 */
			interrupt-names = "event",
			                  "error";       /* in zephyr/dts/arm/st/f4/stm32f4.dtsi:276 */
			status = "disabled";             /* in zephyr/dts/arm/st/f4/stm32f4.dtsi:277 */
			phandle = < 0x1f >;              /* in zephyr/dts/arm/st/f4/stm32f4.dtsi:654 */
		};

		/* node '/soc/i2c@40005800' defined in zephyr/dts/arm/st/f4/stm32f4.dtsi:280 */
		i2c2: i2c@40005800 {
			compatible = "st,stm32-i2c-v1";  /* in zephyr/dts/arm/st/f4/stm32f4.dtsi:281 */
			clock-frequency = < 0x186a0 >;   /* in zephyr/dts/arm/st/f4/stm32f4.dtsi:282 */
			#address-cells = < 0x1 >;        /* in zephyr/dts/arm/st/f4/stm32f4.dtsi:283 */
			#size-cells = < 0x0 >;           /* in zephyr/dts/arm/st/f4/stm32f4.dtsi:284 */
			reg = < 0x40005800 0x400 >;      /* in zephyr/dts/arm/st/f4/stm32f4.dtsi:285 */
			clocks = < &rcc 0x40 0x400000 >; /* in zephyr/dts/arm/st/f4/stm32f4.dtsi:286 */
			interrupts = < 0x21 0x0 >,
			             < 0x22 0x0 >;       /* in zephyr/dts/arm/st/f4/stm32f4.dtsi:287 */
			interrupt-names = "event",
			                  "error";       /* in zephyr/dts/arm/st/f4/stm32f4.dtsi:288 */
			status = "disabled";             /* in zephyr/dts/arm/st/f4/stm32f4.dtsi:289 */
			phandle = < 0x20 >;              /* in zephyr/dts/arm/st/f4/stm32f4.dtsi:662 */
		};

		/* node '/soc/i2c@40005c00' defined in zephyr/dts/arm/st/f4/stm32f4.dtsi:292 */
		i2c3: sdp_i2c: i2c@40005c00 {
			compatible = "st,stm32-i2c-v1";  /* in zephyr/dts/arm/st/f4/stm32f4.dtsi:293 */
			clock-frequency = < 0x186a0 >;   /* in zephyr/dts/arm/st/f4/stm32f4.dtsi:294 */
			#address-cells = < 0x1 >;        /* in zephyr/dts/arm/st/f4/stm32f4.dtsi:295 */
			#size-cells = < 0x0 >;           /* in zephyr/dts/arm/st/f4/stm32f4.dtsi:296 */
			reg = < 0x40005c00 0x400 >;      /* in zephyr/dts/arm/st/f4/stm32f4.dtsi:297 */
			clocks = < &rcc 0x40 0x800000 >; /* in zephyr/dts/arm/st/f4/stm32f4.dtsi:298 */
			interrupts = < 0x48 0x0 >,
			             < 0x49 0x0 >;       /* in zephyr/dts/arm/st/f4/stm32f4.dtsi:299 */
			interrupt-names = "event",
			                  "error";       /* in zephyr/dts/arm/st/f4/stm32f4.dtsi:300 */
			status = "disabled";             /* in zephyr/dts/arm/st/f4/stm32f4.dtsi:301 */
			phandle = < 0x21 >;              /* in zephyr/dts/arm/st/f4/stm32f4.dtsi:670 */
		};

		/* node '/soc/spi@40013000' defined in zephyr/dts/arm/st/f4/stm32f4.dtsi:304 */
		spi1: arduino_spi: spi@40013000 {
			compatible = "st,stm32-spi";   /* in zephyr/dts/arm/st/f4/stm32f4.dtsi:305 */
			#address-cells = < 0x1 >;      /* in zephyr/dts/arm/st/f4/stm32f4.dtsi:306 */
			#size-cells = < 0x0 >;         /* in zephyr/dts/arm/st/f4/stm32f4.dtsi:307 */
			reg = < 0x40013000 0x400 >;    /* in zephyr/dts/arm/st/f4/stm32f4.dtsi:308 */
			clocks = < &rcc 0x44 0x1000 >; /* in zephyr/dts/arm/st/f4/stm32f4.dtsi:309 */
			interrupts = < 0x23 0x5 >;     /* in zephyr/dts/arm/st/f4/stm32f4.dtsi:310 */
			status = "disabled";           /* in zephyr/dts/arm/st/f4/stm32f4.dtsi:311 */
		};

		/* node '/soc/usb@50000000' defined in zephyr/dts/arm/st/f4/stm32f4.dtsi:314 */
		usbotg_fs: usb@50000000 {
			compatible = "st,stm32-otgfs";  /* in zephyr/dts/arm/st/f4/stm32f4.dtsi:315 */
			reg = < 0x50000000 0x40000 >;   /* in zephyr/dts/arm/st/f4/stm32f4.dtsi:316 */
			interrupts = < 0x43 0x0 >;      /* in zephyr/dts/arm/st/f4/stm32f4.dtsi:317 */
			interrupt-names = "otgfs";      /* in zephyr/dts/arm/st/f4/stm32f4.dtsi:318 */
			ram-size = < 0x500 >;           /* in zephyr/dts/arm/st/f4/stm32f4.dtsi:320 */
			maximum-speed = "full-speed";   /* in zephyr/dts/arm/st/f4/stm32f4.dtsi:321 */
			phys = < &otgfs_phy >;          /* in zephyr/dts/arm/st/f4/stm32f4.dtsi:322 */
			status = "disabled";            /* in zephyr/dts/arm/st/f4/stm32f4.dtsi:325 */
			num-bidir-endpoints = < 0x6 >;  /* in zephyr/dts/arm/st/f4/stm32f469.dtsi:20 */
			clocks = < &rcc 0x34 0x80 >,
			         < &rcc 0x7 0x1b008c >; /* in zephyr/dts/arm/st/f4/stm32f469.dtsi:21 */
		};

		/* node '/soc/timers@40010000' defined in zephyr/dts/arm/st/f4/stm32f4.dtsi:328 */
		timers1: timers@40010000 {
			compatible = "st,stm32-timers"; /* in zephyr/dts/arm/st/f4/stm32f4.dtsi:329 */
			reg = < 0x40010000 0x400 >;     /* in zephyr/dts/arm/st/f4/stm32f4.dtsi:330 */
			clocks = < &rcc 0x44 0x1 >,
			         < &rcc 0xd 0xff >;     /* in zephyr/dts/arm/st/f4/stm32f4.dtsi:331 */
			resets = < &rctl 0x480 >;       /* in zephyr/dts/arm/st/f4/stm32f4.dtsi:333 */
			interrupts = < 0x18 0x0 >,
			             < 0x19 0x0 >,
			             < 0x1a 0x0 >,
			             < 0x1b 0x0 >;      /* in zephyr/dts/arm/st/f4/stm32f4.dtsi:334 */
			interrupt-names = "brk",
			                  "up",
			                  "trgcom",
			                  "cc";         /* in zephyr/dts/arm/st/f4/stm32f4.dtsi:335 */
			st,prescaler = < 0x0 >;         /* in zephyr/dts/arm/st/f4/stm32f4.dtsi:336 */
			status = "disabled";            /* in zephyr/dts/arm/st/f4/stm32f4.dtsi:337 */

			/* node '/soc/timers@40010000/pwm' defined in zephyr/dts/arm/st/f4/stm32f4.dtsi:339 */
			pwm {
				compatible = "st,stm32-pwm"; /* in zephyr/dts/arm/st/f4/stm32f4.dtsi:340 */
				status = "disabled";         /* in zephyr/dts/arm/st/f4/stm32f4.dtsi:341 */
				#pwm-cells = < 0x3 >;        /* in zephyr/dts/arm/st/f4/stm32f4.dtsi:342 */
			};

			/* node '/soc/timers@40010000/qdec' defined in zephyr/dts/arm/st/f4/stm32f4.dtsi:345 */
			qdec {
				compatible = "st,stm32-qdec";    /* in zephyr/dts/arm/st/f4/stm32f4.dtsi:346 */
				st,input-filter-level = < 0x0 >; /* in zephyr/dts/arm/st/f4/stm32f4.dtsi:347 */
				status = "disabled";             /* in zephyr/dts/arm/st/f4/stm32f4.dtsi:348 */
			};
		};

		/* node '/soc/timers@40000000' defined in zephyr/dts/arm/st/f4/stm32f4.dtsi:352 */
		timers2: timers@40000000 {
			compatible = "st,stm32-timers"; /* in zephyr/dts/arm/st/f4/stm32f4.dtsi:353 */
			reg = < 0x40000000 0x400 >;     /* in zephyr/dts/arm/st/f4/stm32f4.dtsi:354 */
			clocks = < &rcc 0x40 0x1 >,
			         < &rcc 0xc 0xff >;     /* in zephyr/dts/arm/st/f4/stm32f4.dtsi:355 */
			resets = < &rctl 0x400 >;       /* in zephyr/dts/arm/st/f4/stm32f4.dtsi:357 */
			interrupts = < 0x1c 0x0 >;      /* in zephyr/dts/arm/st/f4/stm32f4.dtsi:358 */
			interrupt-names = "global";     /* in zephyr/dts/arm/st/f4/stm32f4.dtsi:359 */
			st,prescaler = < 0x0 >;         /* in zephyr/dts/arm/st/f4/stm32f4.dtsi:360 */
			status = "disabled";            /* in zephyr/dts/arm/st/f4/stm32f4.dtsi:361 */

			/* node '/soc/timers@40000000/pwm' defined in zephyr/dts/arm/st/f4/stm32f4.dtsi:363 */
			pwm {
				compatible = "st,stm32-pwm"; /* in zephyr/dts/arm/st/f4/stm32f4.dtsi:364 */
				status = "disabled";         /* in zephyr/dts/arm/st/f4/stm32f4.dtsi:365 */
				#pwm-cells = < 0x3 >;        /* in zephyr/dts/arm/st/f4/stm32f4.dtsi:366 */
			};

			/* node '/soc/timers@40000000/counter' defined in zephyr/dts/arm/st/f4/stm32f4.dtsi:369 */
			counter {
				compatible = "st,stm32-counter"; /* in zephyr/dts/arm/st/f4/stm32f4.dtsi:370 */
				status = "disabled";             /* in zephyr/dts/arm/st/f4/stm32f4.dtsi:371 */
			};

			/* node '/soc/timers@40000000/qdec' defined in zephyr/dts/arm/st/f4/stm32f4.dtsi:374 */
			qdec {
				compatible = "st,stm32-qdec";    /* in zephyr/dts/arm/st/f4/stm32f4.dtsi:375 */
				st,input-filter-level = < 0x0 >; /* in zephyr/dts/arm/st/f4/stm32f4.dtsi:376 */
				status = "disabled";             /* in zephyr/dts/arm/st/f4/stm32f4.dtsi:377 */
			};
		};

		/* node '/soc/timers@40000400' defined in zephyr/dts/arm/st/f4/stm32f4.dtsi:381 */
		timers3: timers@40000400 {
			compatible = "st,stm32-timers"; /* in zephyr/dts/arm/st/f4/stm32f4.dtsi:382 */
			reg = < 0x40000400 0x400 >;     /* in zephyr/dts/arm/st/f4/stm32f4.dtsi:383 */
			clocks = < &rcc 0x40 0x2 >,
			         < &rcc 0xc 0xff >;     /* in zephyr/dts/arm/st/f4/stm32f4.dtsi:384 */
			resets = < &rctl 0x401 >;       /* in zephyr/dts/arm/st/f4/stm32f4.dtsi:386 */
			interrupts = < 0x1d 0x0 >;      /* in zephyr/dts/arm/st/f4/stm32f4.dtsi:387 */
			interrupt-names = "global";     /* in zephyr/dts/arm/st/f4/stm32f4.dtsi:388 */
			st,prescaler = < 0x0 >;         /* in zephyr/dts/arm/st/f4/stm32f4.dtsi:389 */
			status = "disabled";            /* in zephyr/dts/arm/st/f4/stm32f4.dtsi:390 */

			/* node '/soc/timers@40000400/pwm' defined in zephyr/dts/arm/st/f4/stm32f4.dtsi:392 */
			pwm {
				compatible = "st,stm32-pwm"; /* in zephyr/dts/arm/st/f4/stm32f4.dtsi:393 */
				status = "disabled";         /* in zephyr/dts/arm/st/f4/stm32f4.dtsi:394 */
				#pwm-cells = < 0x3 >;        /* in zephyr/dts/arm/st/f4/stm32f4.dtsi:395 */
			};

			/* node '/soc/timers@40000400/counter' defined in zephyr/dts/arm/st/f4/stm32f4.dtsi:398 */
			counter {
				compatible = "st,stm32-counter"; /* in zephyr/dts/arm/st/f4/stm32f4.dtsi:399 */
				status = "disabled";             /* in zephyr/dts/arm/st/f4/stm32f4.dtsi:400 */
			};

			/* node '/soc/timers@40000400/qdec' defined in zephyr/dts/arm/st/f4/stm32f4.dtsi:403 */
			qdec {
				compatible = "st,stm32-qdec";    /* in zephyr/dts/arm/st/f4/stm32f4.dtsi:404 */
				st,input-filter-level = < 0x0 >; /* in zephyr/dts/arm/st/f4/stm32f4.dtsi:405 */
				status = "disabled";             /* in zephyr/dts/arm/st/f4/stm32f4.dtsi:406 */
			};
		};

		/* node '/soc/timers@40000800' defined in zephyr/dts/arm/st/f4/stm32f4.dtsi:410 */
		timers4: timers@40000800 {
			compatible = "st,stm32-timers"; /* in zephyr/dts/arm/st/f4/stm32f4.dtsi:411 */
			reg = < 0x40000800 0x400 >;     /* in zephyr/dts/arm/st/f4/stm32f4.dtsi:412 */
			clocks = < &rcc 0x40 0x4 >,
			         < &rcc 0xc 0xff >;     /* in zephyr/dts/arm/st/f4/stm32f4.dtsi:413 */
			resets = < &rctl 0x402 >;       /* in zephyr/dts/arm/st/f4/stm32f4.dtsi:415 */
			interrupts = < 0x1e 0x0 >;      /* in zephyr/dts/arm/st/f4/stm32f4.dtsi:416 */
			interrupt-names = "global";     /* in zephyr/dts/arm/st/f4/stm32f4.dtsi:417 */
			st,prescaler = < 0x0 >;         /* in zephyr/dts/arm/st/f4/stm32f4.dtsi:418 */
			status = "disabled";            /* in zephyr/dts/arm/st/f4/stm32f4.dtsi:419 */

			/* node '/soc/timers@40000800/pwm' defined in zephyr/dts/arm/st/f4/stm32f4.dtsi:421 */
			pwm {
				compatible = "st,stm32-pwm"; /* in zephyr/dts/arm/st/f4/stm32f4.dtsi:422 */
				status = "disabled";         /* in zephyr/dts/arm/st/f4/stm32f4.dtsi:423 */
				#pwm-cells = < 0x3 >;        /* in zephyr/dts/arm/st/f4/stm32f4.dtsi:424 */
			};

			/* node '/soc/timers@40000800/counter' defined in zephyr/dts/arm/st/f4/stm32f4.dtsi:427 */
			counter {
				compatible = "st,stm32-counter"; /* in zephyr/dts/arm/st/f4/stm32f4.dtsi:428 */
				status = "disabled";             /* in zephyr/dts/arm/st/f4/stm32f4.dtsi:429 */
			};

			/* node '/soc/timers@40000800/qdec' defined in zephyr/dts/arm/st/f4/stm32f4.dtsi:432 */
			qdec {
				compatible = "st,stm32-qdec";    /* in zephyr/dts/arm/st/f4/stm32f4.dtsi:433 */
				st,input-filter-level = < 0x0 >; /* in zephyr/dts/arm/st/f4/stm32f4.dtsi:434 */
				status = "disabled";             /* in zephyr/dts/arm/st/f4/stm32f4.dtsi:435 */
			};
		};

		/* node '/soc/timers@40000c00' defined in zephyr/dts/arm/st/f4/stm32f4.dtsi:439 */
		timers5: timers@40000c00 {
			compatible = "st,stm32-timers"; /* in zephyr/dts/arm/st/f4/stm32f4.dtsi:440 */
			reg = < 0x40000c00 0x400 >;     /* in zephyr/dts/arm/st/f4/stm32f4.dtsi:441 */
			clocks = < &rcc 0x40 0x8 >,
			         < &rcc 0xc 0xff >;     /* in zephyr/dts/arm/st/f4/stm32f4.dtsi:442 */
			resets = < &rctl 0x403 >;       /* in zephyr/dts/arm/st/f4/stm32f4.dtsi:444 */
			interrupts = < 0x32 0x0 >;      /* in zephyr/dts/arm/st/f4/stm32f4.dtsi:445 */
			interrupt-names = "global";     /* in zephyr/dts/arm/st/f4/stm32f4.dtsi:446 */
			st,prescaler = < 0x0 >;         /* in zephyr/dts/arm/st/f4/stm32f4.dtsi:447 */
			status = "disabled";            /* in zephyr/dts/arm/st/f4/stm32f4.dtsi:448 */

			/* node '/soc/timers@40000c00/pwm' defined in zephyr/dts/arm/st/f4/stm32f4.dtsi:450 */
			pwm {
				compatible = "st,stm32-pwm"; /* in zephyr/dts/arm/st/f4/stm32f4.dtsi:451 */
				status = "disabled";         /* in zephyr/dts/arm/st/f4/stm32f4.dtsi:452 */
				#pwm-cells = < 0x3 >;        /* in zephyr/dts/arm/st/f4/stm32f4.dtsi:453 */
			};

			/* node '/soc/timers@40000c00/counter' defined in zephyr/dts/arm/st/f4/stm32f4.dtsi:456 */
			counter {
				compatible = "st,stm32-counter"; /* in zephyr/dts/arm/st/f4/stm32f4.dtsi:457 */
				status = "disabled";             /* in zephyr/dts/arm/st/f4/stm32f4.dtsi:458 */
			};

			/* node '/soc/timers@40000c00/qdec' defined in zephyr/dts/arm/st/f4/stm32f4.dtsi:461 */
			qdec {
				compatible = "st,stm32-qdec";    /* in zephyr/dts/arm/st/f4/stm32f4.dtsi:462 */
				st,input-filter-level = < 0x0 >; /* in zephyr/dts/arm/st/f4/stm32f4.dtsi:463 */
				status = "disabled";             /* in zephyr/dts/arm/st/f4/stm32f4.dtsi:464 */
			};
		};

		/* node '/soc/timers@40014000' defined in zephyr/dts/arm/st/f4/stm32f4.dtsi:468 */
		timers9: timers@40014000 {
			compatible = "st,stm32-timers"; /* in zephyr/dts/arm/st/f4/stm32f4.dtsi:469 */
			reg = < 0x40014000 0x400 >;     /* in zephyr/dts/arm/st/f4/stm32f4.dtsi:470 */
			clocks = < &rcc 0x44 0x10000 >,
			         < &rcc 0xd 0xff >;     /* in zephyr/dts/arm/st/f4/stm32f4.dtsi:471 */
			resets = < &rctl 0x490 >;       /* in zephyr/dts/arm/st/f4/stm32f4.dtsi:473 */
			interrupts = < 0x18 0x0 >;      /* in zephyr/dts/arm/st/f4/stm32f4.dtsi:474 */
			interrupt-names = "global";     /* in zephyr/dts/arm/st/f4/stm32f4.dtsi:475 */
			st,prescaler = < 0x0 >;         /* in zephyr/dts/arm/st/f4/stm32f4.dtsi:476 */
			status = "disabled";            /* in zephyr/dts/arm/st/f4/stm32f4.dtsi:477 */

			/* node '/soc/timers@40014000/pwm' defined in zephyr/dts/arm/st/f4/stm32f4.dtsi:479 */
			pwm {
				compatible = "st,stm32-pwm"; /* in zephyr/dts/arm/st/f4/stm32f4.dtsi:480 */
				status = "disabled";         /* in zephyr/dts/arm/st/f4/stm32f4.dtsi:481 */
				#pwm-cells = < 0x3 >;        /* in zephyr/dts/arm/st/f4/stm32f4.dtsi:482 */
			};

			/* node '/soc/timers@40014000/counter' defined in zephyr/dts/arm/st/f4/stm32f4.dtsi:485 */
			counter {
				compatible = "st,stm32-counter"; /* in zephyr/dts/arm/st/f4/stm32f4.dtsi:486 */
				status = "disabled";             /* in zephyr/dts/arm/st/f4/stm32f4.dtsi:487 */
			};
		};

		/* node '/soc/timers@40014400' defined in zephyr/dts/arm/st/f4/stm32f4.dtsi:491 */
		timers10: timers@40014400 {
			compatible = "st,stm32-timers"; /* in zephyr/dts/arm/st/f4/stm32f4.dtsi:492 */
			reg = < 0x40014400 0x400 >;     /* in zephyr/dts/arm/st/f4/stm32f4.dtsi:493 */
			clocks = < &rcc 0x44 0x20000 >,
			         < &rcc 0xd 0xff >;     /* in zephyr/dts/arm/st/f4/stm32f4.dtsi:494 */
			resets = < &rctl 0x491 >;       /* in zephyr/dts/arm/st/f4/stm32f4.dtsi:496 */
			interrupts = < 0x19 0x0 >;      /* in zephyr/dts/arm/st/f4/stm32f4.dtsi:497 */
			interrupt-names = "global";     /* in zephyr/dts/arm/st/f4/stm32f4.dtsi:498 */
			st,prescaler = < 0x0 >;         /* in zephyr/dts/arm/st/f4/stm32f4.dtsi:499 */
			status = "disabled";            /* in zephyr/dts/arm/st/f4/stm32f4.dtsi:500 */

			/* node '/soc/timers@40014400/pwm' defined in zephyr/dts/arm/st/f4/stm32f4.dtsi:502 */
			pwm {
				compatible = "st,stm32-pwm"; /* in zephyr/dts/arm/st/f4/stm32f4.dtsi:503 */
				status = "disabled";         /* in zephyr/dts/arm/st/f4/stm32f4.dtsi:504 */
				#pwm-cells = < 0x3 >;        /* in zephyr/dts/arm/st/f4/stm32f4.dtsi:505 */
			};

			/* node '/soc/timers@40014400/counter' defined in zephyr/dts/arm/st/f4/stm32f4.dtsi:508 */
			counter {
				compatible = "st,stm32-counter"; /* in zephyr/dts/arm/st/f4/stm32f4.dtsi:509 */
				status = "disabled";             /* in zephyr/dts/arm/st/f4/stm32f4.dtsi:510 */
			};
		};

		/* node '/soc/timers@40014800' defined in zephyr/dts/arm/st/f4/stm32f4.dtsi:514 */
		timers11: timers@40014800 {
			compatible = "st,stm32-timers"; /* in zephyr/dts/arm/st/f4/stm32f4.dtsi:515 */
			reg = < 0x40014800 0x400 >;     /* in zephyr/dts/arm/st/f4/stm32f4.dtsi:516 */
			clocks = < &rcc 0x44 0x40000 >,
			         < &rcc 0xd 0xff >;     /* in zephyr/dts/arm/st/f4/stm32f4.dtsi:517 */
			resets = < &rctl 0x492 >;       /* in zephyr/dts/arm/st/f4/stm32f4.dtsi:519 */
			interrupts = < 0x1a 0x0 >;      /* in zephyr/dts/arm/st/f4/stm32f4.dtsi:520 */
			interrupt-names = "global";     /* in zephyr/dts/arm/st/f4/stm32f4.dtsi:521 */
			st,prescaler = < 0x0 >;         /* in zephyr/dts/arm/st/f4/stm32f4.dtsi:522 */
			status = "disabled";            /* in zephyr/dts/arm/st/f4/stm32f4.dtsi:523 */

			/* node '/soc/timers@40014800/pwm' defined in zephyr/dts/arm/st/f4/stm32f4.dtsi:525 */
			pwm {
				compatible = "st,stm32-pwm"; /* in zephyr/dts/arm/st/f4/stm32f4.dtsi:526 */
				status = "disabled";         /* in zephyr/dts/arm/st/f4/stm32f4.dtsi:527 */
				#pwm-cells = < 0x3 >;        /* in zephyr/dts/arm/st/f4/stm32f4.dtsi:528 */
			};

			/* node '/soc/timers@40014800/counter' defined in zephyr/dts/arm/st/f4/stm32f4.dtsi:531 */
			counter {
				compatible = "st,stm32-counter"; /* in zephyr/dts/arm/st/f4/stm32f4.dtsi:532 */
				status = "disabled";             /* in zephyr/dts/arm/st/f4/stm32f4.dtsi:533 */
			};
		};

		/* node '/soc/rtc@40002800' defined in zephyr/dts/arm/st/f4/stm32f4.dtsi:537 */
		rtc: rtc@40002800 {
			compatible = "st,stm32-rtc";       /* in zephyr/dts/arm/st/f4/stm32f4.dtsi:538 */
			reg = < 0x40002800 0x400 >;        /* in zephyr/dts/arm/st/f4/stm32f4.dtsi:539 */
			interrupts = < 0x29 0x0 >;         /* in zephyr/dts/arm/st/f4/stm32f4.dtsi:540 */
			clocks = < &rcc 0x40 0x10000000 >; /* in zephyr/dts/arm/st/f4/stm32f4.dtsi:541 */
			prescaler = < 0x8000 >;            /* in zephyr/dts/arm/st/f4/stm32f4.dtsi:542 */
			alarms-count = < 0x2 >;            /* in zephyr/dts/arm/st/f4/stm32f4.dtsi:543 */
			alrm-exti-line = < 0x11 >;         /* in zephyr/dts/arm/st/f4/stm32f4.dtsi:544 */
			status = "disabled";               /* in zephyr/dts/arm/st/f4/stm32f4.dtsi:545 */

			/* node '/soc/rtc@40002800/backup_regs' defined in zephyr/dts/arm/st/f4/stm32f4.dtsi:547 */
			bbram: backup_regs {
				compatible = "st,stm32-bbram"; /* in zephyr/dts/arm/st/f4/stm32f4.dtsi:548 */
				st,backup-regs = < 0x14 >;     /* in zephyr/dts/arm/st/f4/stm32f4.dtsi:549 */
				status = "disabled";           /* in zephyr/dts/arm/st/f4/stm32f4.dtsi:550 */
			};
		};

		/* node '/soc/adc@40012000' defined in zephyr/dts/arm/st/f4/stm32f4.dtsi:554 */
		adc1: adc@40012000 {
			compatible = "st,stm32f4-adc",
			             "st,stm32-adc";                                 /* in zephyr/dts/arm/st/f4/stm32f4.dtsi:555 */
			reg = < 0x40012000 0x400 >;                                  /* in zephyr/dts/arm/st/f4/stm32f4.dtsi:556 */
			clocks = < &rcc 0x44 0x100 >;                                /* in zephyr/dts/arm/st/f4/stm32f4.dtsi:557 */
			clock-names = "adcx";                                        /* in zephyr/dts/arm/st/f4/stm32f4.dtsi:558 */
			interrupts = < 0x12 0x0 >;                                   /* in zephyr/dts/arm/st/f4/stm32f4.dtsi:559 */
			#io-channel-cells = < 0x1 >;                                 /* in zephyr/dts/arm/st/f4/stm32f4.dtsi:560 */
			resolutions = < 0x607804 0x517804 0x427804 0x337804 >;       /* in zephyr/dts/arm/st/f4/stm32f4.dtsi:561 */
			sampling-times = < 0x3 0xf 0x1c 0x38 0x54 0x70 0x90 0x1e0 >; /* in zephyr/dts/arm/st/f4/stm32f4.dtsi:565 */
			st,adc-clock-source = "SYNC";                                /* in zephyr/dts/arm/st/f4/stm32f4.dtsi:566 */
			st,adc-sequencer = "programmable";                           /* in zephyr/dts/arm/st/f4/stm32f4.dtsi:567 */
			st,adc-oversampler = "none";                                 /* in zephyr/dts/arm/st/f4/stm32f4.dtsi:568 */
			st,adc-internal-regulator = "none";                          /* in zephyr/dts/arm/st/f4/stm32f4.dtsi:569 */
			status = "disabled";                                         /* in zephyr/dts/arm/st/f4/stm32f4.dtsi:570 */
			phandle = < 0x1e >;                                          /* in zephyr/dts/arm/st/f4/stm32f427.dtsi:140 */
		};

		/* node '/soc/dma@40026000' defined in zephyr/dts/arm/st/f4/stm32f4.dtsi:573 */
		dma1: dma@40026000 {
			compatible = "st,stm32-dma-v1";                                                      /* in zephyr/dts/arm/st/f4/stm32f4.dtsi:574 */
			#dma-cells = < 0x4 >;                                                                /* in zephyr/dts/arm/st/f4/stm32f4.dtsi:575 */
			reg = < 0x40026000 0x400 >;                                                          /* in zephyr/dts/arm/st/f4/stm32f4.dtsi:576 */
			interrupts = < 0xb 0x0 0xc 0x0 0xd 0x0 0xe 0x0 0xf 0x0 0x10 0x0 0x11 0x0 0x2f 0x0 >; /* in zephyr/dts/arm/st/f4/stm32f4.dtsi:577 */
			clocks = < &rcc 0x30 0x200000 >;                                                     /* in zephyr/dts/arm/st/f4/stm32f4.dtsi:578 */
			status = "disabled";                                                                 /* in zephyr/dts/arm/st/f4/stm32f4.dtsi:579 */
			phandle = < 0x6 >;                                                                   /* in zephyr/dts/arm/st/f4/stm32f401.dtsi:58 */
		};

		/* node '/soc/dma@40026400' defined in zephyr/dts/arm/st/f4/stm32f4.dtsi:582 */
		dma2: dma@40026400 {
			compatible = "st,stm32-dma-v1";                                                           /* in zephyr/dts/arm/st/f4/stm32f4.dtsi:583 */
			#dma-cells = < 0x4 >;                                                                     /* in zephyr/dts/arm/st/f4/stm32f4.dtsi:584 */
			reg = < 0x40026400 0x400 >;                                                               /* in zephyr/dts/arm/st/f4/stm32f4.dtsi:585 */
			interrupts = < 0x38 0x0 0x39 0x0 0x3a 0x0 0x3b 0x0 0x3c 0x0 0x44 0x0 0x45 0x0 0x46 0x0 >; /* in zephyr/dts/arm/st/f4/stm32f4.dtsi:586 */
			clocks = < &rcc 0x30 0x400000 >;                                                          /* in zephyr/dts/arm/st/f4/stm32f4.dtsi:587 */
			st,mem2mem;                                                                               /* in zephyr/dts/arm/st/f4/stm32f4.dtsi:588 */
			status = "disabled";                                                                      /* in zephyr/dts/arm/st/f4/stm32f4.dtsi:589 */
			phandle = < 0x1a >;                                                                       /* in zephyr/dts/arm/st/f4/stm32f427.dtsi:122 */
		};

		/* node '/soc/sdmmc@40012c00' defined in zephyr/dts/arm/st/f4/stm32f4.dtsi:592 */
		sdmmc1: sdmmc@40012c00 {
			compatible = "st,stm32-sdmmc";   /* in zephyr/dts/arm/st/f4/stm32f4.dtsi:593 */
			reg = < 0x40012c00 0x400 >;      /* in zephyr/dts/arm/st/f4/stm32f4.dtsi:594 */
			resets = < &rctl 0x48b >;        /* in zephyr/dts/arm/st/f4/stm32f4.dtsi:597 */
			interrupts = < 0x31 0x0 >;       /* in zephyr/dts/arm/st/f4/stm32f4.dtsi:598 */
			status = "disabled";             /* in zephyr/dts/arm/st/f4/stm32f4.dtsi:599 */
			clocks = < &rcc 0x44 0x800 >,
			         < &rcc 0x1 0x11c008c >; /* in zephyr/dts/arm/st/f4/stm32f469.dtsi:15 */
		};

		/* node '/soc/spi@40003800' defined in zephyr/dts/arm/st/f4/stm32f401.dtsi:21 */
		spi2: spi@40003800 {
			compatible = "st,stm32-spi";   /* in zephyr/dts/arm/st/f4/stm32f401.dtsi:22 */
			#address-cells = < 0x1 >;      /* in zephyr/dts/arm/st/f4/stm32f401.dtsi:23 */
			#size-cells = < 0x0 >;         /* in zephyr/dts/arm/st/f4/stm32f401.dtsi:24 */
			reg = < 0x40003800 0x400 >;    /* in zephyr/dts/arm/st/f4/stm32f401.dtsi:25 */
			clocks = < &rcc 0x40 0x4000 >; /* in zephyr/dts/arm/st/f4/stm32f401.dtsi:26 */
			interrupts = < 0x24 0x5 >;     /* in zephyr/dts/arm/st/f4/stm32f401.dtsi:27 */
			status = "disabled";           /* in zephyr/dts/arm/st/f4/stm32f401.dtsi:28 */
		};

		/* node '/soc/spi@40003c00' defined in zephyr/dts/arm/st/f4/stm32f401.dtsi:31 */
		spi3: spi@40003c00 {
			compatible = "st,stm32-spi";   /* in zephyr/dts/arm/st/f4/stm32f401.dtsi:32 */
			#address-cells = < 0x1 >;      /* in zephyr/dts/arm/st/f4/stm32f401.dtsi:33 */
			#size-cells = < 0x0 >;         /* in zephyr/dts/arm/st/f4/stm32f401.dtsi:34 */
			reg = < 0x40003c00 0x400 >;    /* in zephyr/dts/arm/st/f4/stm32f401.dtsi:35 */
			clocks = < &rcc 0x40 0x8000 >; /* in zephyr/dts/arm/st/f4/stm32f401.dtsi:36 */
			interrupts = < 0x33 0x5 >;     /* in zephyr/dts/arm/st/f4/stm32f401.dtsi:37 */
			status = "disabled";           /* in zephyr/dts/arm/st/f4/stm32f401.dtsi:38 */
		};

		/* node '/soc/spi@40013400' defined in zephyr/dts/arm/st/f4/stm32f401.dtsi:41 */
		spi4: spi@40013400 {
			compatible = "st,stm32-spi";   /* in zephyr/dts/arm/st/f4/stm32f427.dtsi:67 */
			#address-cells = < 0x1 >;      /* in zephyr/dts/arm/st/f4/stm32f427.dtsi:68 */
			#size-cells = < 0x0 >;         /* in zephyr/dts/arm/st/f4/stm32f427.dtsi:69 */
			reg = < 0x40013400 0x400 >;    /* in zephyr/dts/arm/st/f4/stm32f427.dtsi:70 */
			clocks = < &rcc 0x44 0x2000 >; /* in zephyr/dts/arm/st/f4/stm32f427.dtsi:71 */
			interrupts = < 0x54 0x5 >;     /* in zephyr/dts/arm/st/f4/stm32f427.dtsi:72 */
			status = "disabled";           /* in zephyr/dts/arm/st/f4/stm32f427.dtsi:73 */
		};

		/* node '/soc/i2s@40003800' defined in zephyr/dts/arm/st/f4/stm32f401.dtsi:51 */
		i2s2: i2s@40003800 {
			compatible = "st,stm32-i2s";        /* in zephyr/dts/arm/st/f4/stm32f401.dtsi:52 */
			#address-cells = < 0x1 >;           /* in zephyr/dts/arm/st/f4/stm32f401.dtsi:53 */
			#size-cells = < 0x0 >;              /* in zephyr/dts/arm/st/f4/stm32f401.dtsi:54 */
			reg = < 0x40003800 0x400 >;         /* in zephyr/dts/arm/st/f4/stm32f401.dtsi:55 */
			clocks = < &rcc 0x40 0x4000 >;      /* in zephyr/dts/arm/st/f4/stm32f401.dtsi:56 */
			interrupts = < 0x24 0x5 >;          /* in zephyr/dts/arm/st/f4/stm32f401.dtsi:57 */
			dmas = < &dma1 0x4 0x0 0x400 0x3 >,
			       < &dma1 0x3 0x0 0x400 0x3 >; /* in zephyr/dts/arm/st/f4/stm32f401.dtsi:58 */
			dma-names = "tx",
			            "rx";                   /* in zephyr/dts/arm/st/f4/stm32f401.dtsi:60 */
			status = "disabled";                /* in zephyr/dts/arm/st/f4/stm32f401.dtsi:61 */
		};

		/* node '/soc/i2s@40003c00' defined in zephyr/dts/arm/st/f4/stm32f401.dtsi:64 */
		i2s3: i2s@40003c00 {
			compatible = "st,stm32-i2s";        /* in zephyr/dts/arm/st/f4/stm32f401.dtsi:65 */
			#address-cells = < 0x1 >;           /* in zephyr/dts/arm/st/f4/stm32f401.dtsi:66 */
			#size-cells = < 0x0 >;              /* in zephyr/dts/arm/st/f4/stm32f401.dtsi:67 */
			reg = < 0x40003c00 0x400 >;         /* in zephyr/dts/arm/st/f4/stm32f401.dtsi:68 */
			clocks = < &rcc 0x40 0x8000 >;      /* in zephyr/dts/arm/st/f4/stm32f401.dtsi:69 */
			interrupts = < 0x33 0x5 >;          /* in zephyr/dts/arm/st/f4/stm32f401.dtsi:70 */
			dmas = < &dma1 0x5 0x0 0x400 0x3 >,
			       < &dma1 0x0 0x0 0x400 0x3 >; /* in zephyr/dts/arm/st/f4/stm32f401.dtsi:71 */
			dma-names = "tx",
			            "rx";                   /* in zephyr/dts/arm/st/f4/stm32f401.dtsi:73 */
			status = "disabled";                /* in zephyr/dts/arm/st/f4/stm32f401.dtsi:74 */
		};

		/* node '/soc/serial@40004800' defined in zephyr/dts/arm/st/f4/stm32f405.dtsi:51 */
		usart3: serial@40004800 {
			compatible = "st,stm32-usart",
			             "st,stm32-uart";   /* in zephyr/dts/arm/st/f4/stm32f405.dtsi:52 */
			reg = < 0x40004800 0x400 >;     /* in zephyr/dts/arm/st/f4/stm32f405.dtsi:53 */
			clocks = < &rcc 0x40 0x40000 >; /* in zephyr/dts/arm/st/f4/stm32f405.dtsi:54 */
			resets = < &rctl 0x412 >;       /* in zephyr/dts/arm/st/f4/stm32f405.dtsi:55 */
			interrupts = < 0x27 0x0 >;      /* in zephyr/dts/arm/st/f4/stm32f405.dtsi:56 */
			status = "disabled";            /* in zephyr/dts/arm/st/f4/stm32f405.dtsi:57 */
		};

		/* node '/soc/serial@40004c00' defined in zephyr/dts/arm/st/f4/stm32f405.dtsi:60 */
		uart4: serial@40004c00 {
			compatible = "st,stm32-uart";   /* in zephyr/dts/arm/st/f4/stm32f405.dtsi:61 */
			reg = < 0x40004c00 0x400 >;     /* in zephyr/dts/arm/st/f4/stm32f405.dtsi:62 */
			clocks = < &rcc 0x40 0x80000 >; /* in zephyr/dts/arm/st/f4/stm32f405.dtsi:63 */
			resets = < &rctl 0x413 >;       /* in zephyr/dts/arm/st/f4/stm32f405.dtsi:64 */
			interrupts = < 0x34 0x0 >;      /* in zephyr/dts/arm/st/f4/stm32f405.dtsi:65 */
			status = "disabled";            /* in zephyr/dts/arm/st/f4/stm32f405.dtsi:66 */
		};

		/* node '/soc/serial@40005000' defined in zephyr/dts/arm/st/f4/stm32f405.dtsi:69 */
		uart5: serial@40005000 {
			compatible = "st,stm32-uart";                 /* in zephyr/dts/arm/st/f4/stm32f405.dtsi:70 */
			reg = < 0x40005000 0x400 >;                   /* in zephyr/dts/arm/st/f4/stm32f405.dtsi:71 */
			clocks = < &rcc 0x40 0x100000 >;              /* in zephyr/dts/arm/st/f4/stm32f405.dtsi:72 */
			resets = < &rctl 0x414 >;                     /* in zephyr/dts/arm/st/f4/stm32f405.dtsi:73 */
			interrupts = < 0x35 0x0 >;                    /* in zephyr/dts/arm/st/f4/stm32f405.dtsi:74 */
			pinctrl-0 = < &uart5_tx_pc12 &uart5_rx_pd2 >; /* in zephyr/boards/adi/sdp_k1/adi_sdp_k1.dts:87 */
			pinctrl-names = "default";                    /* in zephyr/boards/adi/sdp_k1/adi_sdp_k1.dts:88 */
			current-speed = < 0x1c200 >;                  /* in zephyr/boards/adi/sdp_k1/adi_sdp_k1.dts:89 */
			status = "okay";                              /* in zephyr/boards/adi/sdp_k1/adi_sdp_k1.dts:90 */
		};

		/* node '/soc/timers@40001000' defined in zephyr/dts/arm/st/f4/stm32f405.dtsi:78 */
		timers6: timers@40001000 {
			compatible = "st,stm32-timers"; /* in zephyr/dts/arm/st/f4/stm32f405.dtsi:79 */
			reg = < 0x40001000 0x400 >;     /* in zephyr/dts/arm/st/f4/stm32f405.dtsi:80 */
			clocks = < &rcc 0x40 0x10 >,
			         < &rcc 0xc 0xff >;     /* in zephyr/dts/arm/st/f4/stm32f405.dtsi:81 */
			resets = < &rctl 0x404 >;       /* in zephyr/dts/arm/st/f4/stm32f405.dtsi:83 */
			interrupts = < 0x36 0x0 >;      /* in zephyr/dts/arm/st/f4/stm32f405.dtsi:84 */
			interrupt-names = "global";     /* in zephyr/dts/arm/st/f4/stm32f405.dtsi:85 */
			st,prescaler = < 0x0 >;         /* in zephyr/dts/arm/st/f4/stm32f405.dtsi:86 */
			status = "disabled";            /* in zephyr/dts/arm/st/f4/stm32f405.dtsi:87 */

			/* node '/soc/timers@40001000/counter' defined in zephyr/dts/arm/st/f4/stm32f405.dtsi:89 */
			counter {
				compatible = "st,stm32-counter"; /* in zephyr/dts/arm/st/f4/stm32f405.dtsi:90 */
				status = "disabled";             /* in zephyr/dts/arm/st/f4/stm32f405.dtsi:91 */
			};
		};

		/* node '/soc/timers@40001400' defined in zephyr/dts/arm/st/f4/stm32f405.dtsi:95 */
		timers7: timers@40001400 {
			compatible = "st,stm32-timers"; /* in zephyr/dts/arm/st/f4/stm32f405.dtsi:96 */
			reg = < 0x40001400 0x400 >;     /* in zephyr/dts/arm/st/f4/stm32f405.dtsi:97 */
			clocks = < &rcc 0x40 0x20 >,
			         < &rcc 0xc 0xff >;     /* in zephyr/dts/arm/st/f4/stm32f405.dtsi:98 */
			resets = < &rctl 0x405 >;       /* in zephyr/dts/arm/st/f4/stm32f405.dtsi:100 */
			interrupts = < 0x37 0x0 >;      /* in zephyr/dts/arm/st/f4/stm32f405.dtsi:101 */
			interrupt-names = "global";     /* in zephyr/dts/arm/st/f4/stm32f405.dtsi:102 */
			st,prescaler = < 0x0 >;         /* in zephyr/dts/arm/st/f4/stm32f405.dtsi:103 */
			status = "disabled";            /* in zephyr/dts/arm/st/f4/stm32f405.dtsi:104 */

			/* node '/soc/timers@40001400/counter' defined in zephyr/dts/arm/st/f4/stm32f405.dtsi:106 */
			counter {
				compatible = "st,stm32-counter"; /* in zephyr/dts/arm/st/f4/stm32f405.dtsi:107 */
				status = "disabled";             /* in zephyr/dts/arm/st/f4/stm32f405.dtsi:108 */
			};
		};

		/* node '/soc/timers@40010400' defined in zephyr/dts/arm/st/f4/stm32f405.dtsi:112 */
		timers8: timers@40010400 {
			compatible = "st,stm32-timers"; /* in zephyr/dts/arm/st/f4/stm32f405.dtsi:113 */
			reg = < 0x40010400 0x400 >;     /* in zephyr/dts/arm/st/f4/stm32f405.dtsi:114 */
			clocks = < &rcc 0x44 0x2 >,
			         < &rcc 0xd 0xff >;     /* in zephyr/dts/arm/st/f4/stm32f405.dtsi:115 */
			resets = < &rctl 0x481 >;       /* in zephyr/dts/arm/st/f4/stm32f405.dtsi:117 */
			interrupts = < 0x2b 0x0 >,
			             < 0x2c 0x0 >,
			             < 0x2d 0x0 >,
			             < 0x2e 0x0 >;      /* in zephyr/dts/arm/st/f4/stm32f405.dtsi:118 */
			interrupt-names = "brk",
			                  "up",
			                  "trgcom",
			                  "cc";         /* in zephyr/dts/arm/st/f4/stm32f405.dtsi:119 */
			st,prescaler = < 0x0 >;         /* in zephyr/dts/arm/st/f4/stm32f405.dtsi:120 */
			status = "disabled";            /* in zephyr/dts/arm/st/f4/stm32f405.dtsi:121 */

			/* node '/soc/timers@40010400/pwm' defined in zephyr/dts/arm/st/f4/stm32f405.dtsi:123 */
			pwm {
				compatible = "st,stm32-pwm"; /* in zephyr/dts/arm/st/f4/stm32f405.dtsi:124 */
				status = "disabled";         /* in zephyr/dts/arm/st/f4/stm32f405.dtsi:125 */
				#pwm-cells = < 0x3 >;        /* in zephyr/dts/arm/st/f4/stm32f405.dtsi:126 */
			};

			/* node '/soc/timers@40010400/qdec' defined in zephyr/dts/arm/st/f4/stm32f405.dtsi:129 */
			qdec {
				compatible = "st,stm32-qdec";    /* in zephyr/dts/arm/st/f4/stm32f405.dtsi:130 */
				st,input-filter-level = < 0x0 >; /* in zephyr/dts/arm/st/f4/stm32f405.dtsi:131 */
				status = "disabled";             /* in zephyr/dts/arm/st/f4/stm32f405.dtsi:132 */
			};
		};

		/* node '/soc/timers@40001800' defined in zephyr/dts/arm/st/f4/stm32f405.dtsi:136 */
		timers12: timers@40001800 {
			compatible = "st,stm32-timers"; /* in zephyr/dts/arm/st/f4/stm32f405.dtsi:137 */
			reg = < 0x40001800 0x400 >;     /* in zephyr/dts/arm/st/f4/stm32f405.dtsi:138 */
			clocks = < &rcc 0x40 0x40 >,
			         < &rcc 0xc 0xff >;     /* in zephyr/dts/arm/st/f4/stm32f405.dtsi:139 */
			resets = < &rctl 0x406 >;       /* in zephyr/dts/arm/st/f4/stm32f405.dtsi:141 */
			interrupts = < 0x2b 0x0 >;      /* in zephyr/dts/arm/st/f4/stm32f405.dtsi:142 */
			interrupt-names = "global";     /* in zephyr/dts/arm/st/f4/stm32f405.dtsi:143 */
			st,prescaler = < 0x0 >;         /* in zephyr/dts/arm/st/f4/stm32f405.dtsi:144 */
			status = "disabled";            /* in zephyr/dts/arm/st/f4/stm32f405.dtsi:145 */

			/* node '/soc/timers@40001800/pwm' defined in zephyr/dts/arm/st/f4/stm32f405.dtsi:147 */
			pwm {
				compatible = "st,stm32-pwm"; /* in zephyr/dts/arm/st/f4/stm32f405.dtsi:148 */
				status = "disabled";         /* in zephyr/dts/arm/st/f4/stm32f405.dtsi:149 */
				#pwm-cells = < 0x3 >;        /* in zephyr/dts/arm/st/f4/stm32f405.dtsi:150 */
			};

			/* node '/soc/timers@40001800/counter' defined in zephyr/dts/arm/st/f4/stm32f405.dtsi:153 */
			counter {
				compatible = "st,stm32-counter"; /* in zephyr/dts/arm/st/f4/stm32f405.dtsi:154 */
				status = "disabled";             /* in zephyr/dts/arm/st/f4/stm32f405.dtsi:155 */
			};
		};

		/* node '/soc/timers@40001c00' defined in zephyr/dts/arm/st/f4/stm32f405.dtsi:159 */
		timers13: timers@40001c00 {
			compatible = "st,stm32-timers"; /* in zephyr/dts/arm/st/f4/stm32f405.dtsi:160 */
			reg = < 0x40001c00 0x400 >;     /* in zephyr/dts/arm/st/f4/stm32f405.dtsi:161 */
			clocks = < &rcc 0x40 0x80 >,
			         < &rcc 0xc 0xff >;     /* in zephyr/dts/arm/st/f4/stm32f405.dtsi:162 */
			resets = < &rctl 0x407 >;       /* in zephyr/dts/arm/st/f4/stm32f405.dtsi:164 */
			interrupts = < 0x2c 0x0 >;      /* in zephyr/dts/arm/st/f4/stm32f405.dtsi:165 */
			interrupt-names = "global";     /* in zephyr/dts/arm/st/f4/stm32f405.dtsi:166 */
			st,prescaler = < 0x0 >;         /* in zephyr/dts/arm/st/f4/stm32f405.dtsi:167 */
			status = "disabled";            /* in zephyr/dts/arm/st/f4/stm32f405.dtsi:168 */

			/* node '/soc/timers@40001c00/pwm' defined in zephyr/dts/arm/st/f4/stm32f405.dtsi:170 */
			pwm {
				compatible = "st,stm32-pwm"; /* in zephyr/dts/arm/st/f4/stm32f405.dtsi:171 */
				status = "disabled";         /* in zephyr/dts/arm/st/f4/stm32f405.dtsi:172 */
				#pwm-cells = < 0x3 >;        /* in zephyr/dts/arm/st/f4/stm32f405.dtsi:173 */
			};

			/* node '/soc/timers@40001c00/counter' defined in zephyr/dts/arm/st/f4/stm32f405.dtsi:176 */
			counter {
				compatible = "st,stm32-counter"; /* in zephyr/dts/arm/st/f4/stm32f405.dtsi:177 */
				status = "disabled";             /* in zephyr/dts/arm/st/f4/stm32f405.dtsi:178 */
			};
		};

		/* node '/soc/timers@40002000' defined in zephyr/dts/arm/st/f4/stm32f405.dtsi:182 */
		timers14: timers@40002000 {
			compatible = "st,stm32-timers"; /* in zephyr/dts/arm/st/f4/stm32f405.dtsi:183 */
			reg = < 0x40002000 0x400 >;     /* in zephyr/dts/arm/st/f4/stm32f405.dtsi:184 */
			clocks = < &rcc 0x40 0x100 >,
			         < &rcc 0xc 0xff >;     /* in zephyr/dts/arm/st/f4/stm32f405.dtsi:185 */
			resets = < &rctl 0x408 >;       /* in zephyr/dts/arm/st/f4/stm32f405.dtsi:187 */
			interrupts = < 0x2d 0x0 >;      /* in zephyr/dts/arm/st/f4/stm32f405.dtsi:188 */
			interrupt-names = "global";     /* in zephyr/dts/arm/st/f4/stm32f405.dtsi:189 */
			st,prescaler = < 0x0 >;         /* in zephyr/dts/arm/st/f4/stm32f405.dtsi:190 */
			status = "disabled";            /* in zephyr/dts/arm/st/f4/stm32f405.dtsi:191 */

			/* node '/soc/timers@40002000/pwm' defined in zephyr/dts/arm/st/f4/stm32f405.dtsi:193 */
			pwm {
				compatible = "st,stm32-pwm"; /* in zephyr/dts/arm/st/f4/stm32f405.dtsi:194 */
				status = "disabled";         /* in zephyr/dts/arm/st/f4/stm32f405.dtsi:195 */
				#pwm-cells = < 0x3 >;        /* in zephyr/dts/arm/st/f4/stm32f405.dtsi:196 */
			};

			/* node '/soc/timers@40002000/counter' defined in zephyr/dts/arm/st/f4/stm32f405.dtsi:199 */
			counter {
				compatible = "st,stm32-counter"; /* in zephyr/dts/arm/st/f4/stm32f405.dtsi:200 */
				status = "disabled";             /* in zephyr/dts/arm/st/f4/stm32f405.dtsi:201 */
			};
		};

		/* node '/soc/usb@40040000' defined in zephyr/dts/arm/st/f4/stm32f405.dtsi:205 */
		usbotg_hs: zephyr_udc0: usb@40040000 {
			compatible = "st,stm32-otghs";                                                                                      /* in zephyr/dts/arm/st/f4/stm32f405.dtsi:206 */
			reg = < 0x40040000 0x40000 >;                                                                                       /* in zephyr/dts/arm/st/f4/stm32f405.dtsi:207 */
			interrupts = < 0x4d 0x0 >,
			             < 0x4a 0x0 >,
			             < 0x4b 0x0 >;                                                                                          /* in zephyr/dts/arm/st/f4/stm32f405.dtsi:208 */
			interrupt-names = "otghs",
			                  "ep1_out",
			                  "ep1_in";                                                                                         /* in zephyr/dts/arm/st/f4/stm32f405.dtsi:209 */
			ram-size = < 0x1000 >;                                                                                              /* in zephyr/dts/arm/st/f4/stm32f405.dtsi:211 */
			num-bidir-endpoints = < 0x9 >;                                                                                      /* in zephyr/dts/arm/st/f4/stm32f469.dtsi:26 */
			pinctrl-0 = < &usb_otg_hs_ulpi_ck_pa5 &usb_otg_hs_ulpi_d0_pa3 &usb_otg_hs_ulpi_d1_pb0 &usb_otg_hs_ulpi_d2_pb1
			              &usb_otg_hs_ulpi_d3_pb10 &usb_otg_hs_ulpi_d4_pb11 &usb_otg_hs_ulpi_d5_pb12 &usb_otg_hs_ulpi_d6_pb13
			              &usb_otg_hs_ulpi_d7_pb5 &usb_otg_hs_ulpi_stp_pc0 &usb_otg_hs_ulpi_dir_pc2 &usb_otg_hs_ulpi_nxt_pc3 >; /* in zephyr/boards/adi/sdp_k1/adi_sdp_k1.dts:94 */
			pinctrl-names = "default";                                                                                          /* in zephyr/boards/adi/sdp_k1/adi_sdp_k1.dts:106 */
			maximum-speed = "high-speed";                                                                                       /* in zephyr/boards/adi/sdp_k1/adi_sdp_k1.dts:107 */
			clocks = < &rcc 0x30 0x60000000 >,
			         < &rcc 0x7 0xff >;                                                                                         /* in zephyr/boards/adi/sdp_k1/adi_sdp_k1.dts:109 */
			phys = < &otghs_ulpi_phy >;                                                                                         /* in zephyr/boards/adi/sdp_k1/adi_sdp_k1.dts:111 */
			status = "okay";                                                                                                    /* in zephyr/boards/adi/sdp_k1/adi_sdp_k1.dts:112 */
		};

		/* node '/soc/can@40006400' defined in zephyr/dts/arm/st/f4/stm32f405.dtsi:219 */
		can1: can@40006400 {
			compatible = "st,stm32-bxcan";    /* in zephyr/dts/arm/st/f4/stm32f405.dtsi:220 */
			reg = < 0x40006400 0x400 >;       /* in zephyr/dts/arm/st/f4/stm32f405.dtsi:221 */
			interrupts = < 0x13 0x0 >,
			             < 0x14 0x0 >,
			             < 0x15 0x0 >,
			             < 0x16 0x0 >;        /* in zephyr/dts/arm/st/f4/stm32f405.dtsi:222 */
			interrupt-names = "TX",
			                  "RX0",
			                  "RX1",
			                  "SCE";          /* in zephyr/dts/arm/st/f4/stm32f405.dtsi:223 */
			clocks = < &rcc 0x40 0x2000000 >; /* in zephyr/dts/arm/st/f4/stm32f405.dtsi:224 */
			status = "disabled";              /* in zephyr/dts/arm/st/f4/stm32f405.dtsi:225 */
		};

		/* node '/soc/can@40006800' defined in zephyr/dts/arm/st/f4/stm32f405.dtsi:228 */
		can2: can@40006800 {
			compatible = "st,stm32-bxcan";    /* in zephyr/dts/arm/st/f4/stm32f405.dtsi:229 */
			reg = < 0x40006800 0x400 >;       /* in zephyr/dts/arm/st/f4/stm32f405.dtsi:230 */
			interrupts = < 0x3f 0x0 >,
			             < 0x40 0x0 >,
			             < 0x41 0x0 >,
			             < 0x42 0x0 >;        /* in zephyr/dts/arm/st/f4/stm32f405.dtsi:231 */
			interrupt-names = "TX",
			                  "RX0",
			                  "RX1",
			                  "SCE";          /* in zephyr/dts/arm/st/f4/stm32f405.dtsi:232 */
			clocks = < &rcc 0x40 0x6000000 >; /* in zephyr/dts/arm/st/f4/stm32f405.dtsi:234 */
			master-can-reg = < 0x40006400 >;  /* in zephyr/dts/arm/st/f4/stm32f405.dtsi:235 */
			status = "disabled";              /* in zephyr/dts/arm/st/f4/stm32f405.dtsi:236 */
		};

		/* node '/soc/rng@50060800' defined in zephyr/dts/arm/st/f4/stm32f405.dtsi:239 */
		rng: rng@50060800 {
			compatible = "st,stm32-rng"; /* in zephyr/dts/arm/st/f4/stm32f405.dtsi:240 */
			reg = < 0x50060800 0x400 >;  /* in zephyr/dts/arm/st/f4/stm32f405.dtsi:241 */
			interrupts = < 0x50 0x0 >;   /* in zephyr/dts/arm/st/f4/stm32f405.dtsi:242 */
			clocks = < &rcc 0x34 0x40 >; /* in zephyr/dts/arm/st/f4/stm32f405.dtsi:243 */
			status = "disabled";         /* in zephyr/dts/arm/st/f4/stm32f405.dtsi:244 */
		};

		/* node '/soc/memory@40024000' defined in zephyr/dts/arm/st/f4/stm32f405.dtsi:247 */
		backup_sram: memory@40024000 {
			compatible = "zephyr,memory-region",
			             "st,stm32-backup-sram";  /* in zephyr/dts/arm/st/f4/stm32f405.dtsi:248 */
			reg = < 0x40024000 0x1000 >;          /* in zephyr/dts/arm/st/f4/stm32f405.dtsi:249 */
			clocks = < &rcc 0x30 0x40000 >;       /* in zephyr/dts/arm/st/f4/stm32f405.dtsi:250 */
			zephyr,memory-region = "BACKUP_SRAM"; /* in zephyr/dts/arm/st/f4/stm32f405.dtsi:251 */
			status = "disabled";                  /* in zephyr/dts/arm/st/f4/stm32f405.dtsi:252 */
		};

		/* node '/soc/adc@40012100' defined in zephyr/dts/arm/st/f4/stm32f405.dtsi:255 */
		adc2: adc@40012100 {
			compatible = "st,stm32-adc";                                 /* in zephyr/dts/arm/st/f4/stm32f405.dtsi:256 */
			reg = < 0x40012100 0x50 >;                                   /* in zephyr/dts/arm/st/f4/stm32f405.dtsi:257 */
			clocks = < &rcc 0x44 0x200 >;                                /* in zephyr/dts/arm/st/f4/stm32f405.dtsi:258 */
			clock-names = "adcx";                                        /* in zephyr/dts/arm/st/f4/stm32f405.dtsi:259 */
			interrupts = < 0x12 0x0 >;                                   /* in zephyr/dts/arm/st/f4/stm32f405.dtsi:260 */
			#io-channel-cells = < 0x1 >;                                 /* in zephyr/dts/arm/st/f4/stm32f405.dtsi:261 */
			resolutions = < 0x607804 0x517804 0x427804 0x337804 >;       /* in zephyr/dts/arm/st/f4/stm32f405.dtsi:262 */
			sampling-times = < 0x3 0xf 0x1c 0x38 0x54 0x70 0x90 0x1e0 >; /* in zephyr/dts/arm/st/f4/stm32f405.dtsi:266 */
			st,adc-clock-source = "SYNC";                                /* in zephyr/dts/arm/st/f4/stm32f405.dtsi:267 */
			st,adc-sequencer = "programmable";                           /* in zephyr/dts/arm/st/f4/stm32f405.dtsi:268 */
			st,adc-oversampler = "none";                                 /* in zephyr/dts/arm/st/f4/stm32f405.dtsi:269 */
			st,adc-internal-regulator = "none";                          /* in zephyr/dts/arm/st/f4/stm32f405.dtsi:270 */
			status = "disabled";                                         /* in zephyr/dts/arm/st/f4/stm32f405.dtsi:271 */
		};

		/* node '/soc/adc@40012200' defined in zephyr/dts/arm/st/f4/stm32f405.dtsi:274 */
		adc3: adc@40012200 {
			compatible = "st,stm32-adc";                                 /* in zephyr/dts/arm/st/f4/stm32f405.dtsi:275 */
			reg = < 0x40012200 0x50 >;                                   /* in zephyr/dts/arm/st/f4/stm32f405.dtsi:276 */
			clocks = < &rcc 0x44 0x400 >;                                /* in zephyr/dts/arm/st/f4/stm32f405.dtsi:277 */
			clock-names = "adcx";                                        /* in zephyr/dts/arm/st/f4/stm32f405.dtsi:278 */
			interrupts = < 0x12 0x0 >;                                   /* in zephyr/dts/arm/st/f4/stm32f405.dtsi:279 */
			#io-channel-cells = < 0x1 >;                                 /* in zephyr/dts/arm/st/f4/stm32f405.dtsi:280 */
			resolutions = < 0x607804 0x517804 0x427804 0x337804 >;       /* in zephyr/dts/arm/st/f4/stm32f405.dtsi:281 */
			sampling-times = < 0x3 0xf 0x1c 0x38 0x54 0x70 0x90 0x1e0 >; /* in zephyr/dts/arm/st/f4/stm32f405.dtsi:285 */
			st,adc-clock-source = "SYNC";                                /* in zephyr/dts/arm/st/f4/stm32f405.dtsi:286 */
			st,adc-sequencer = "programmable";                           /* in zephyr/dts/arm/st/f4/stm32f405.dtsi:287 */
			st,adc-oversampler = "none";                                 /* in zephyr/dts/arm/st/f4/stm32f405.dtsi:288 */
			st,adc-internal-regulator = "none";                          /* in zephyr/dts/arm/st/f4/stm32f405.dtsi:289 */
			status = "disabled";                                         /* in zephyr/dts/arm/st/f4/stm32f405.dtsi:290 */
		};

		/* node '/soc/dac@40007400' defined in zephyr/dts/arm/st/f4/stm32f405.dtsi:293 */
		dac1: dac@40007400 {
			compatible = "st,stm32-dac";       /* in zephyr/dts/arm/st/f4/stm32f429.dtsi:15 */
			reg = < 0x40007400 0x400 >;        /* in zephyr/dts/arm/st/f4/stm32f429.dtsi:16 */
			clocks = < &rcc 0x40 0x20000000 >; /* in zephyr/dts/arm/st/f4/stm32f429.dtsi:17 */
			status = "disabled";               /* in zephyr/dts/arm/st/f4/stm32f429.dtsi:18 */
			#io-channel-cells = < 0x1 >;       /* in zephyr/dts/arm/st/f4/stm32f429.dtsi:19 */
		};

		/* node '/soc/ethernet@40028000' defined in zephyr/dts/arm/st/f4/stm32f407.dtsi:13 */
		ethernet@40028000 {
			reg = < 0x40028000 0x8000 >;                 /* in zephyr/dts/arm/st/f4/stm32f407.dtsi:14 */
			compatible = "st,stm32-ethernet-controller"; /* in zephyr/dts/arm/st/f4/stm32f407.dtsi:15 */
			clock-names = "stm-eth";                     /* in zephyr/dts/arm/st/f4/stm32f407.dtsi:16 */
			clocks = < &rcc 0x30 0x2000000 >;            /* in zephyr/dts/arm/st/f4/stm32f407.dtsi:17 */

			/* node '/soc/ethernet@40028000/ethernet' defined in zephyr/dts/arm/st/f4/stm32f407.dtsi:19 */
			mac: ethernet {
				compatible = "st,stm32-ethernet";  /* in zephyr/dts/arm/st/f4/stm32f407.dtsi:20 */
				interrupts = < 0x3d 0x0 >;         /* in zephyr/dts/arm/st/f4/stm32f407.dtsi:21 */
				clock-names = "mac-clk-tx",
				              "mac-clk-rx",
				              "mac-clk-ptp";       /* in zephyr/dts/arm/st/f4/stm32f407.dtsi:22 */
				clocks = < &rcc 0x30 0x4000000 >,
				         < &rcc 0x30 0x8000000 >,
				         < &rcc 0x30 0x10000000 >; /* in zephyr/dts/arm/st/f4/stm32f407.dtsi:24 */
				status = "disabled";               /* in zephyr/dts/arm/st/f4/stm32f407.dtsi:27 */
			};

			/* node '/soc/ethernet@40028000/mdio' defined in zephyr/dts/arm/st/f4/stm32f407.dtsi:30 */
			mdio: mdio {
				compatible = "st,stm32-mdio"; /* in zephyr/dts/arm/st/f4/stm32f407.dtsi:31 */
				#address-cells = < 0x1 >;     /* in zephyr/dts/arm/st/f4/stm32f407.dtsi:32 */
				#size-cells = < 0x0 >;        /* in zephyr/dts/arm/st/f4/stm32f407.dtsi:33 */
				status = "disabled";          /* in zephyr/dts/arm/st/f4/stm32f407.dtsi:34 */
			};
		};

		/* node '/soc/serial@40007800' defined in zephyr/dts/arm/st/f4/stm32f427.dtsi:48 */
		uart7: serial@40007800 {
			compatible = "st,stm32-uart";      /* in zephyr/dts/arm/st/f4/stm32f427.dtsi:49 */
			reg = < 0x40007800 0x400 >;        /* in zephyr/dts/arm/st/f4/stm32f427.dtsi:50 */
			clocks = < &rcc 0x40 0x40000000 >; /* in zephyr/dts/arm/st/f4/stm32f427.dtsi:51 */
			resets = < &rctl 0x41e >;          /* in zephyr/dts/arm/st/f4/stm32f427.dtsi:52 */
			interrupts = < 0x52 0x0 >;         /* in zephyr/dts/arm/st/f4/stm32f427.dtsi:53 */
			status = "disabled";               /* in zephyr/dts/arm/st/f4/stm32f427.dtsi:54 */
		};

		/* node '/soc/serial@40007c00' defined in zephyr/dts/arm/st/f4/stm32f427.dtsi:57 */
		uart8: serial@40007c00 {
			compatible = "st,stm32-uart";      /* in zephyr/dts/arm/st/f4/stm32f427.dtsi:58 */
			reg = < 0x40007c00 0x400 >;        /* in zephyr/dts/arm/st/f4/stm32f427.dtsi:59 */
			clocks = < &rcc 0x40 0x80000000 >; /* in zephyr/dts/arm/st/f4/stm32f427.dtsi:60 */
			resets = < &rctl 0x41f >;          /* in zephyr/dts/arm/st/f4/stm32f427.dtsi:61 */
			interrupts = < 0x53 0x0 >;         /* in zephyr/dts/arm/st/f4/stm32f427.dtsi:62 */
			status = "disabled";               /* in zephyr/dts/arm/st/f4/stm32f427.dtsi:63 */
		};

		/* node '/soc/spi@40015000' defined in zephyr/dts/arm/st/f4/stm32f427.dtsi:79 */
		spi5: sdp_spi: spi@40015000 {
			compatible = "st,stm32-spi";                                 /* in zephyr/dts/arm/st/f4/stm32f427.dtsi:80 */
			#address-cells = < 0x1 >;                                    /* in zephyr/dts/arm/st/f4/stm32f427.dtsi:81 */
			#size-cells = < 0x0 >;                                       /* in zephyr/dts/arm/st/f4/stm32f427.dtsi:82 */
			reg = < 0x40015000 0x400 >;                                  /* in zephyr/dts/arm/st/f4/stm32f427.dtsi:83 */
			clocks = < &rcc 0x44 0x100000 >;                             /* in zephyr/dts/arm/st/f4/stm32f427.dtsi:84 */
			interrupts = < 0x55 0x5 >;                                   /* in zephyr/dts/arm/st/f4/stm32f427.dtsi:85 */
			pinctrl-0 = < &spi5_sck_ph6 &spi5_miso_pf8 &spi5_mosi_pf9 >; /* in zephyr/boards/adi/sdp_k1/adi_sdp_120pin_connector.dtsi:106 */
			pinctrl-names = "default";                                   /* in zephyr/boards/adi/sdp_k1/adi_sdp_120pin_connector.dtsi:107 */
			cs-gpios = < &sdp_k1_120_hdr 0x54 0x11 >;                    /* in zephyr/boards/adi/sdp_k1/adi_sdp_120pin_connector.dtsi:108 */
			status = "okay";                                             /* in zephyr/boards/adi/sdp_k1/adi_sdp_120pin_connector.dtsi:109 */
		};

		/* node '/soc/spi@40015400' defined in zephyr/dts/arm/st/f4/stm32f427.dtsi:92 */
		spi6: spi@40015400 {
			compatible = "st,stm32-spi";     /* in zephyr/dts/arm/st/f4/stm32f427.dtsi:93 */
			#address-cells = < 0x1 >;        /* in zephyr/dts/arm/st/f4/stm32f427.dtsi:94 */
			#size-cells = < 0x0 >;           /* in zephyr/dts/arm/st/f4/stm32f427.dtsi:95 */
			reg = < 0x40015400 0x400 >;      /* in zephyr/dts/arm/st/f4/stm32f427.dtsi:96 */
			clocks = < &rcc 0x44 0x200000 >; /* in zephyr/dts/arm/st/f4/stm32f427.dtsi:97 */
			interrupts = < 0x56 0x5 >;       /* in zephyr/dts/arm/st/f4/stm32f427.dtsi:98 */
			status = "disabled";             /* in zephyr/dts/arm/st/f4/stm32f427.dtsi:99 */
		};

		/* node '/soc/memory-controller@a0000000' defined in zephyr/dts/arm/st/f4/stm32f427.dtsi:102 */
		fmc: memory-controller@a0000000 {
			compatible = "st,stm32-fmc"; /* in zephyr/dts/arm/st/f4/stm32f427.dtsi:103 */
			reg = < 0xa0000000 0x400 >;  /* in zephyr/dts/arm/st/f4/stm32f427.dtsi:104 */
			clocks = < &rcc 0x38 0x1 >;  /* in zephyr/dts/arm/st/f4/stm32f427.dtsi:105 */
			status = "disabled";         /* in zephyr/dts/arm/st/f4/stm32f427.dtsi:106 */

			/* node '/soc/memory-controller@a0000000/sdram' defined in zephyr/dts/arm/st/f4/stm32f427.dtsi:108 */
			sdram: sdram {
				compatible = "st,stm32-fmc-sdram"; /* in zephyr/dts/arm/st/f4/stm32f427.dtsi:109 */
				#address-cells = < 0x1 >;          /* in zephyr/dts/arm/st/f4/stm32f427.dtsi:110 */
				#size-cells = < 0x0 >;             /* in zephyr/dts/arm/st/f4/stm32f427.dtsi:111 */
				status = "disabled";               /* in zephyr/dts/arm/st/f4/stm32f427.dtsi:112 */
			};
		};

		/* node '/soc/sai1@40015804' defined in zephyr/dts/arm/st/f4/stm32f427.dtsi:116 */
		sai1_a: sai1@40015804 {
			compatible = "st,stm32-sai";          /* in zephyr/dts/arm/st/f4/stm32f427.dtsi:117 */
			#address-cells = < 0x1 >;             /* in zephyr/dts/arm/st/f4/stm32f427.dtsi:118 */
			#size-cells = < 0x0 >;                /* in zephyr/dts/arm/st/f4/stm32f427.dtsi:119 */
			reg = < 0x40015804 0x20 >;            /* in zephyr/dts/arm/st/f4/stm32f427.dtsi:120 */
			clocks = < &rcc 0x44 0x400000 >;      /* in zephyr/dts/arm/st/f4/stm32f427.dtsi:121 */
			dmas = < &dma2 0x1 0x0 0x22800 0x0 >; /* in zephyr/dts/arm/st/f4/stm32f427.dtsi:122 */
			status = "disabled";                  /* in zephyr/dts/arm/st/f4/stm32f427.dtsi:124 */
		};

		/* node '/soc/sai1@40015824' defined in zephyr/dts/arm/st/f4/stm32f427.dtsi:127 */
		sai1_b: sai1@40015824 {
			compatible = "st,stm32-sai";          /* in zephyr/dts/arm/st/f4/stm32f427.dtsi:128 */
			#address-cells = < 0x1 >;             /* in zephyr/dts/arm/st/f4/stm32f427.dtsi:129 */
			#size-cells = < 0x0 >;                /* in zephyr/dts/arm/st/f4/stm32f427.dtsi:130 */
			reg = < 0x40015824 0x20 >;            /* in zephyr/dts/arm/st/f4/stm32f427.dtsi:131 */
			clocks = < &rcc 0x44 0x400000 >;      /* in zephyr/dts/arm/st/f4/stm32f427.dtsi:132 */
			dmas = < &dma2 0x5 0x0 0x22800 0x0 >; /* in zephyr/dts/arm/st/f4/stm32f427.dtsi:133 */
			status = "disabled";                  /* in zephyr/dts/arm/st/f4/stm32f427.dtsi:135 */
		};

		/* node '/soc/display-controller@40016800' defined in zephyr/dts/arm/st/f4/stm32f429.dtsi:22 */
		ltdc: display-controller@40016800 {
			compatible = "st,stm32-ltdc";     /* in zephyr/dts/arm/st/f4/stm32f429.dtsi:23 */
			reg = < 0x40016800 0x200 >;       /* in zephyr/dts/arm/st/f4/stm32f429.dtsi:24 */
			interrupts = < 0x58 0x0 >,
			             < 0x59 0x0 >;        /* in zephyr/dts/arm/st/f4/stm32f429.dtsi:25 */
			interrupt-names = "ltdc",
			                  "ltdc_er";      /* in zephyr/dts/arm/st/f4/stm32f429.dtsi:26 */
			clocks = < &rcc 0x44 0x4000000 >; /* in zephyr/dts/arm/st/f4/stm32f429.dtsi:27 */
			resets = < &rctl 0x49a >;         /* in zephyr/dts/arm/st/f4/stm32f429.dtsi:28 */
			status = "disabled";              /* in zephyr/dts/arm/st/f4/stm32f429.dtsi:29 */
		};

		/* node '/soc/dsihost@40016c00' defined in zephyr/dts/arm/st/f4/stm32f469.dtsi:29 */
		mipi_dsi: dsihost@40016c00 {
			compatible = "st,stm32-mipi-dsi"; /* in zephyr/dts/arm/st/f4/stm32f469.dtsi:30 */
			reg = < 0x40016c00 0x800 >;       /* in zephyr/dts/arm/st/f4/stm32f469.dtsi:31 */
			#address-cells = < 0x1 >;         /* in zephyr/dts/arm/st/f4/stm32f469.dtsi:32 */
			#size-cells = < 0x0 >;            /* in zephyr/dts/arm/st/f4/stm32f469.dtsi:33 */
			clock-names = "dsiclk",
			              "refclk",
			              "pixelclk";         /* in zephyr/dts/arm/st/f4/stm32f469.dtsi:34 */
			clocks = < &rcc 0x44 0x8000000 >,
			         < &rcc 0x5 0xff >,
			         < &rcc 0x12 0xff >;      /* in zephyr/dts/arm/st/f4/stm32f469.dtsi:35 */
			resets = < &rctl 0x49b >;         /* in zephyr/dts/arm/st/f4/stm32f469.dtsi:38 */
			status = "disabled";              /* in zephyr/dts/arm/st/f4/stm32f469.dtsi:39 */
		};
	};

	/* node '/cpus' defined in zephyr/dts/arm/st/f4/stm32f4.dtsi:31 */
	cpus {
		#address-cells = < 0x1 >; /* in zephyr/dts/arm/st/f4/stm32f4.dtsi:32 */
		#size-cells = < 0x0 >;    /* in zephyr/dts/arm/st/f4/stm32f4.dtsi:33 */

		/* node '/cpus/cpu@0' defined in zephyr/dts/arm/st/f4/stm32f4.dtsi:35 */
		cpu0: cpu@0 {
			device_type = "cpu";           /* in zephyr/dts/arm/st/f4/stm32f4.dtsi:36 */
			compatible = "arm,cortex-m4f"; /* in zephyr/dts/arm/st/f4/stm32f4.dtsi:37 */
			reg = < 0x0 >;                 /* in zephyr/dts/arm/st/f4/stm32f4.dtsi:38 */
			cpu-power-states = < &stop >;  /* in zephyr/dts/arm/st/f4/stm32f4.dtsi:39 */
		};

		/* node '/cpus/power-states' defined in zephyr/dts/arm/st/f4/stm32f4.dtsi:42 */
		power-states {

			/* node '/cpus/power-states/stop' defined in zephyr/dts/arm/st/f4/stm32f4.dtsi:43 */
			stop: stop {
				compatible = "zephyr,power-state";    /* in zephyr/dts/arm/st/f4/stm32f4.dtsi:44 */
				power-state-name = "suspend-to-idle"; /* in zephyr/dts/arm/st/f4/stm32f4.dtsi:45 */
				min-residency-us = < 0x190 >;         /* in zephyr/dts/arm/st/f4/stm32f4.dtsi:52 */
				exit-latency-us = < 0x12c >;          /* in zephyr/dts/arm/st/f4/stm32f4.dtsi:53 */
				phandle = < 0x1b >;                   /* in zephyr/dts/arm/st/f4/stm32f4.dtsi:39 */
			};
		};
	};

	/* node '/memory@20000000' defined in zephyr/dts/arm/st/f4/stm32f4.dtsi:58 */
	sram0: memory@20000000 {
		compatible = "zephyr,memory-region",
		             "mmio-sram";            /* in zephyr/dts/arm/st/f4/stm32f4.dtsi:59 */
		zephyr,memory-region = "SRAM0";      /* in zephyr/dts/arm/st/f4/stm32f4.dtsi:60 */
		reg = < 0x20000000 0x50000 >;        /* in zephyr/dts/arm/st/f4/stm32f469Xi.dtsi:17 */
	};

	/* node '/clocks' defined in zephyr/dts/arm/st/f4/stm32f4.dtsi:63 */
	clocks {

		/* node '/clocks/clk-hse' defined in zephyr/dts/arm/st/f4/stm32f4.dtsi:64 */
		clk_hse: clk-hse {
			#clock-cells = < 0x0 >;            /* in zephyr/dts/arm/st/f4/stm32f4.dtsi:65 */
			compatible = "st,stm32-hse-clock"; /* in zephyr/dts/arm/st/f4/stm32f4.dtsi:66 */
			clock-frequency = < 0x7a1200 >;    /* in zephyr/boards/adi/sdp_k1/adi_sdp_k1.dts:65 */
			status = "okay";                   /* in zephyr/boards/adi/sdp_k1/adi_sdp_k1.dts:66 */
			phandle = < 0x1c >;                /* in zephyr/boards/adi/sdp_k1/adi_sdp_k1.dts:74 */
		};

		/* node '/clocks/clk-hsi' defined in zephyr/dts/arm/st/f4/stm32f4.dtsi:70 */
		clk_hsi: clk-hsi {
			#clock-cells = < 0x0 >;         /* in zephyr/dts/arm/st/f4/stm32f4.dtsi:71 */
			compatible = "fixed-clock";     /* in zephyr/dts/arm/st/f4/stm32f4.dtsi:72 */
			clock-frequency = < 0xf42400 >; /* in zephyr/dts/arm/st/f4/stm32f4.dtsi:73 */
			status = "disabled";            /* in zephyr/dts/arm/st/f4/stm32f4.dtsi:74 */
		};

		/* node '/clocks/clk-lse' defined in zephyr/dts/arm/st/f4/stm32f4.dtsi:77 */
		clk_lse: clk-lse {
			#clock-cells = < 0x0 >;       /* in zephyr/dts/arm/st/f4/stm32f4.dtsi:78 */
			compatible = "fixed-clock";   /* in zephyr/dts/arm/st/f4/stm32f4.dtsi:79 */
			clock-frequency = < 0x8000 >; /* in zephyr/dts/arm/st/f4/stm32f4.dtsi:80 */
			status = "disabled";          /* in zephyr/dts/arm/st/f4/stm32f4.dtsi:81 */
		};

		/* node '/clocks/clk-lsi' defined in zephyr/dts/arm/st/f4/stm32f4.dtsi:84 */
		clk_lsi: clk-lsi {
			#clock-cells = < 0x0 >;       /* in zephyr/dts/arm/st/f4/stm32f4.dtsi:85 */
			compatible = "fixed-clock";   /* in zephyr/dts/arm/st/f4/stm32f4.dtsi:86 */
			clock-frequency = < 0x7d00 >; /* in zephyr/dts/arm/st/f4/stm32f4.dtsi:87 */
			status = "okay";              /* in zephyr/boards/adi/sdp_k1/adi_sdp_k1.dts:61 */
		};

		/* node '/clocks/pll' defined in zephyr/dts/arm/st/f4/stm32f4.dtsi:91 */
		pll: pll {
			#clock-cells = < 0x0 >;              /* in zephyr/dts/arm/st/f4/stm32f4.dtsi:92 */
			compatible = "st,stm32f4-pll-clock"; /* in zephyr/dts/arm/st/f4/stm32f4.dtsi:93 */
			div-m = < 0x8 >;                     /* in zephyr/boards/adi/sdp_k1/adi_sdp_k1.dts:70 */
			mul-n = < 0x150 >;                   /* in zephyr/boards/adi/sdp_k1/adi_sdp_k1.dts:71 */
			div-p = < 0x2 >;                     /* in zephyr/boards/adi/sdp_k1/adi_sdp_k1.dts:72 */
			div-q = < 0x7 >;                     /* in zephyr/boards/adi/sdp_k1/adi_sdp_k1.dts:73 */
			clocks = < &clk_hse >;               /* in zephyr/boards/adi/sdp_k1/adi_sdp_k1.dts:74 */
			status = "okay";                     /* in zephyr/boards/adi/sdp_k1/adi_sdp_k1.dts:75 */
			phandle = < 0x2 >;                   /* in zephyr/boards/adi/sdp_k1/adi_sdp_k1.dts:79 */
		};

		/* node '/clocks/plli2s' defined in zephyr/dts/arm/st/f4/stm32f401.dtsi:11 */
		plli2s: plli2s {
			#clock-cells = < 0x0 >;                 /* in zephyr/dts/arm/st/f4/stm32f401.dtsi:12 */
			compatible = "st,stm32f4-plli2s-clock"; /* in zephyr/dts/arm/st/f4/stm32f401.dtsi:13 */
			status = "disabled";                    /* in zephyr/dts/arm/st/f4/stm32f401.dtsi:14 */
		};

		/* node '/clocks/pllsai' defined in zephyr/dts/arm/st/f4/stm32f427.dtsi:14 */
		pllsai: pllsai {
			compatible = "st,stm32fx-pllsai-clock"; /* in zephyr/dts/arm/st/f4/stm32f427.dtsi:15 */
			#clock-cells = < 0x0 >;                 /* in zephyr/dts/arm/st/f4/stm32f427.dtsi:16 */
			status = "disabled";                    /* in zephyr/dts/arm/st/f4/stm32f427.dtsi:17 */
		};
	};

	/* node '/mcos' defined in zephyr/dts/arm/st/f4/stm32f4.dtsi:98 */
	mcos {

		/* node '/mcos/mco1' defined in zephyr/dts/arm/st/f4/stm32f4.dtsi:99 */
		mco1: mco1 {
			compatible = "st,stm32-clock-mco"; /* in zephyr/dts/arm/st/f4/stm32f4.dtsi:100 */
			status = "disabled";               /* in zephyr/dts/arm/st/f4/stm32f4.dtsi:101 */
		};

		/* node '/mcos/mco2' defined in zephyr/dts/arm/st/f4/stm32f4.dtsi:104 */
		mco2: mco2 {
			compatible = "st,stm32-clock-mco"; /* in zephyr/dts/arm/st/f4/stm32f4.dtsi:105 */
			status = "disabled";               /* in zephyr/dts/arm/st/f4/stm32f4.dtsi:106 */
		};
	};

	/* node '/power@40007000' defined in zephyr/dts/arm/st/f4/stm32f4.dtsi:603 */
	pwr: power@40007000 {
		compatible = "st,stm32-pwr"; /* in zephyr/dts/arm/st/f4/stm32f4.dtsi:604 */
		reg = < 0x40007000 0x400 >;  /* in zephyr/dts/arm/st/f4/stm32f4.dtsi:605 */
		status = "disabled";         /* in zephyr/dts/arm/st/f4/stm32f4.dtsi:606 */
		wkup-pins-nb = < 0x1 >;      /* in zephyr/dts/arm/st/f4/stm32f4.dtsi:608 */
		#address-cells = < 0x1 >;    /* in zephyr/dts/arm/st/f4/stm32f4.dtsi:610 */
		#size-cells = < 0x0 >;       /* in zephyr/dts/arm/st/f4/stm32f4.dtsi:611 */

		/* node '/power@40007000/wkup-pin@1' defined in zephyr/dts/arm/st/f4/stm32f4.dtsi:613 */
		wkup-pin@1 {
			reg = < 0x1 >;                   /* in zephyr/dts/arm/st/f4/stm32f4.dtsi:614 */
			wkup-gpios = < &gpioa 0x0 0x1 >; /* in zephyr/dts/arm/st/f4/stm32f4.dtsi:615 */
		};
	};

	/* node '/dietemp' defined in zephyr/dts/arm/st/f4/stm32f4.dtsi:619 */
	die_temp: dietemp {
		compatible = "st,stm32-temp-cal"; /* in zephyr/dts/arm/st/f4/stm32f4.dtsi:620 */
		ts-cal1-addr = < 0x1fff7a2c >;    /* in zephyr/dts/arm/st/f4/stm32f4.dtsi:621 */
		ts-cal2-addr = < 0x1fff7a2e >;    /* in zephyr/dts/arm/st/f4/stm32f4.dtsi:622 */
		ts-cal1-temp = < 0x1e >;          /* in zephyr/dts/arm/st/f4/stm32f4.dtsi:623 */
		ts-cal2-temp = < 0x6e >;          /* in zephyr/dts/arm/st/f4/stm32f4.dtsi:624 */
		ts-cal-vrefanalog = < 0xce4 >;    /* in zephyr/dts/arm/st/f4/stm32f4.dtsi:625 */
		status = "disabled";              /* in zephyr/dts/arm/st/f4/stm32f4.dtsi:627 */
		io-channels = < &adc1 0x12 >;     /* in zephyr/dts/arm/st/f4/stm32f427.dtsi:140 */
	};

	/* node '/vref' defined in zephyr/dts/arm/st/f4/stm32f4.dtsi:630 */
	vref: vref {
		compatible = "st,stm32-vref";      /* in zephyr/dts/arm/st/f4/stm32f4.dtsi:631 */
		vrefint-cal-addr = < 0x1fff7a2a >; /* in zephyr/dts/arm/st/f4/stm32f4.dtsi:632 */
		vrefint-cal-mv = < 0xce4 >;        /* in zephyr/dts/arm/st/f4/stm32f4.dtsi:633 */
		io-channels = < &adc1 0x11 >;      /* in zephyr/dts/arm/st/f4/stm32f4.dtsi:634 */
		status = "disabled";               /* in zephyr/dts/arm/st/f4/stm32f4.dtsi:635 */
	};

	/* node '/vbat' defined in zephyr/dts/arm/st/f4/stm32f4.dtsi:638 */
	vbat: vbat {
		compatible = "st,stm32-vbat"; /* in zephyr/dts/arm/st/f4/stm32f4.dtsi:639 */
		ratio = < 0x4 >;              /* in zephyr/dts/arm/st/f4/stm32f4.dtsi:640 */
		io-channels = < &adc1 0x12 >; /* in zephyr/dts/arm/st/f4/stm32f4.dtsi:641 */
		status = "disabled";          /* in zephyr/dts/arm/st/f4/stm32f4.dtsi:642 */
	};

	/* node '/otgfs_phy' defined in zephyr/dts/arm/st/f4/stm32f4.dtsi:645 */
	otgfs_phy: otgfs_phy {
		compatible = "usb-nop-xceiv"; /* in zephyr/dts/arm/st/f4/stm32f4.dtsi:646 */
		#phy-cells = < 0x0 >;         /* in zephyr/dts/arm/st/f4/stm32f4.dtsi:647 */
		phandle = < 0x5 >;            /* in zephyr/dts/arm/st/f4/stm32f4.dtsi:322 */
	};

	/* node '/smbus1' defined in zephyr/dts/arm/st/f4/stm32f4.dtsi:650 */
	smbus1: smbus1 {
		compatible = "st,stm32-smbus"; /* in zephyr/dts/arm/st/f4/stm32f4.dtsi:651 */
		#address-cells = < 0x1 >;      /* in zephyr/dts/arm/st/f4/stm32f4.dtsi:652 */
		#size-cells = < 0x0 >;         /* in zephyr/dts/arm/st/f4/stm32f4.dtsi:653 */
		i2c = < &i2c1 >;               /* in zephyr/dts/arm/st/f4/stm32f4.dtsi:654 */
		status = "disabled";           /* in zephyr/dts/arm/st/f4/stm32f4.dtsi:655 */
	};

	/* node '/smbus2' defined in zephyr/dts/arm/st/f4/stm32f4.dtsi:658 */
	smbus2: smbus2 {
		compatible = "st,stm32-smbus"; /* in zephyr/dts/arm/st/f4/stm32f4.dtsi:659 */
		#address-cells = < 0x1 >;      /* in zephyr/dts/arm/st/f4/stm32f4.dtsi:660 */
		#size-cells = < 0x0 >;         /* in zephyr/dts/arm/st/f4/stm32f4.dtsi:661 */
		i2c = < &i2c2 >;               /* in zephyr/dts/arm/st/f4/stm32f4.dtsi:662 */
		status = "disabled";           /* in zephyr/dts/arm/st/f4/stm32f4.dtsi:663 */
	};

	/* node '/smbus3' defined in zephyr/dts/arm/st/f4/stm32f4.dtsi:666 */
	smbus3: smbus3 {
		compatible = "st,stm32-smbus"; /* in zephyr/dts/arm/st/f4/stm32f4.dtsi:667 */
		#address-cells = < 0x1 >;      /* in zephyr/dts/arm/st/f4/stm32f4.dtsi:668 */
		#size-cells = < 0x0 >;         /* in zephyr/dts/arm/st/f4/stm32f4.dtsi:669 */
		i2c = < &i2c3 >;               /* in zephyr/dts/arm/st/f4/stm32f4.dtsi:670 */
		status = "disabled";           /* in zephyr/dts/arm/st/f4/stm32f4.dtsi:671 */
	};

	/* node '/otghs_fs_phy' defined in zephyr/dts/arm/st/f4/stm32f405.dtsi:302 */
	otghs_fs_phy: otghs_fs_phy {
		compatible = "usb-nop-xceiv"; /* in zephyr/dts/arm/st/f4/stm32f405.dtsi:303 */
		#phy-cells = < 0x0 >;         /* in zephyr/dts/arm/st/f4/stm32f405.dtsi:304 */
	};

	/* node '/memory@10000000' defined in zephyr/dts/arm/st/f4/stm32f469Xi.dtsi:10 */
	ccm0: memory@10000000 {
		compatible = "zephyr,memory-region",
		             "st,stm32-ccm";         /* in zephyr/dts/arm/st/f4/stm32f469Xi.dtsi:11 */
		reg = < 0x10000000 0x10000 >;        /* in zephyr/dts/arm/st/f4/stm32f469Xi.dtsi:12 */
		zephyr,memory-region = "CCM";        /* in zephyr/dts/arm/st/f4/stm32f469Xi.dtsi:13 */
	};

	/* node '/connector' defined in zephyr/boards/adi/sdp_k1/arduino_r3_connector.dtsi:10 */
	arduino_header: sdp_k1_120_hdr: connector {
		compatible = "adi,sdp-120";                /* in zephyr/boards/adi/sdp_k1/adi_sdp_120pin_connector.dtsi:12 */
		#gpio-cells = < 0x2 >;                     /* in zephyr/boards/adi/sdp_k1/adi_sdp_120pin_connector.dtsi:13 */
		gpio-map-mask = < 0xffffffff 0xffffffc0 >; /* in zephyr/boards/adi/sdp_k1/adi_sdp_120pin_connector.dtsi:14 */
		gpio-map-pass-thru = < 0x0 0x3f >;         /* in zephyr/boards/adi/sdp_k1/adi_sdp_120pin_connector.dtsi:15 */
		gpio-map = < 0x20 0x0 &gpiof 0x7 0x0 >,
		           < 0x21 0x0 &gpiod 0xd 0x0 >,
		           < 0x22 0x0 &gpioc 0xb 0x0 >,
		           < 0x24 0x0 &gpioc 0x6 0x0 >,
		           < 0x25 0x0 &gpioc 0x7 0x0 >,
		           < 0x26 0x0 &gpiof 0x6 0x0 >,
		           < 0x2a 0x0 &gpioj 0x0 0x0 >,
		           < 0x2b 0x0 &gpioj 0x3 0x0 >,
		           < 0x2c 0x0 &gpioj 0x5 0x0 >,
		           < 0x2e 0x0 &gpioj 0xd 0x0 >,
		           < 0x2f 0x0 &gpiob 0xe 0x0 >,
		           < 0x3a 0x0 &gpiod 0x6 0x0 >,
		           < 0x3d 0x0 &gpiod 0x5 0x0 >,
		           < 0x47 0x0 &gpioc 0x8 0x0 >,
		           < 0x48 0x0 &gpioe 0x6 0x0 >,
		           < 0x49 0x0 &gpioj 0xe 0x0 >,
		           < 0x4b 0x0 &gpioj 0xc 0x0 >,
		           < 0x4c 0x0 &gpioj 0x4 0x0 >,
		           < 0x4d 0x0 &gpioj 0x1 0x0 >,
		           < 0x4e 0x0 &gpioh 0x7 0x0 >,
		           < 0x4f 0x0 &gpioc 0x9 0x0 >,
		           < 0x51 0x0 &gpioh 0x6 0x0 >,
		           < 0x52 0x0 &gpiof 0x8 0x0 >,
		           < 0x53 0x0 &gpiof 0x9 0x0 >,
		           < 0x54 0x0 &gpiob 0x6 0x0 >,
		           < 0x56 0x0 &gpiog 0xd 0x0 >,
		           < 0x57 0x0 &gpiog 0xe 0x0 >,
		           < 0x58 0x0 &gpioa 0x8 0x0 >,
		           < 0x59 0x0 &gpioe 0x4 0x0 >,
		           < 0x5a 0x0 &gpioe 0x5 0x0 >,
		           < 0x5b 0x0 &gpioe 0x2 0x0 >;    /* in zephyr/boards/adi/sdp_k1/adi_sdp_120pin_connector.dtsi:16 */
		phandle = < 0x19 >;                        /* in zephyr/boards/adi/sdp_k1/adi_sdp_120pin_connector.dtsi:108 */
	};

	/* node '/pmod_spi' defined in zephyr/boards/adi/sdp_k1/adi_sdp_120pin_connector.dtsi:63 */
	pmod_spi {
		compatible = "digilent,pmod";                    /* in zephyr/boards/adi/sdp_k1/adi_sdp_120pin_connector.dtsi:64 */
		#gpio-cells = < 0x2 >;                           /* in zephyr/boards/adi/sdp_k1/adi_sdp_120pin_connector.dtsi:65 */
		gpio-map-mask = < 0xffffffff 0xffffffc0 >;       /* in zephyr/boards/adi/sdp_k1/adi_sdp_120pin_connector.dtsi:66 */
		gpio-map-pass-thru = < 0x0 0x3f >;               /* in zephyr/boards/adi/sdp_k1/adi_sdp_120pin_connector.dtsi:67 */
		gpio-map = < 0x0 0x0 &sdp_k1_120_hdr 0x54 0x0 >,
		           < 0x1 0x0 &sdp_k1_120_hdr 0x52 0x0 >,
		           < 0x2 0x0 &sdp_k1_120_hdr 0x53 0x0 >,
		           < 0x3 0x0 &sdp_k1_120_hdr 0x51 0x0 >,
		           < 0x4 0x0 &sdp_k1_120_hdr 0x22 0x0 >,
		           < 0x5 0x0 &sdp_k1_120_hdr 0x4b 0x0 >,
		           < 0x6 0x0 &sdp_k1_120_hdr 0x2e 0x0 >,
		           < 0x7 0x0 &sdp_k1_120_hdr 0x49 0x0 >; /* in zephyr/boards/adi/sdp_k1/adi_sdp_120pin_connector.dtsi:68 */
		status = "disabled";                             /* in zephyr/boards/adi/sdp_k1/adi_sdp_120pin_connector.dtsi:76 */
	};

	/* node '/pmod_usart' defined in zephyr/boards/adi/sdp_k1/adi_sdp_120pin_connector.dtsi:79 */
	pmod_usart {
		compatible = "digilent,pmod";                    /* in zephyr/boards/adi/sdp_k1/adi_sdp_120pin_connector.dtsi:80 */
		#gpio-cells = < 0x2 >;                           /* in zephyr/boards/adi/sdp_k1/adi_sdp_120pin_connector.dtsi:81 */
		gpio-map-mask = < 0xffffffff 0xffffffc0 >;       /* in zephyr/boards/adi/sdp_k1/adi_sdp_120pin_connector.dtsi:82 */
		gpio-map-pass-thru = < 0x0 0x3f >;               /* in zephyr/boards/adi/sdp_k1/adi_sdp_120pin_connector.dtsi:83 */
		gpio-map = < 0x0 0x0 &sdp_k1_120_hdr 0x2a 0x0 >,
		           < 0x1 0x0 &sdp_k1_120_hdr 0x3d 0x0 >,
		           < 0x2 0x0 &sdp_k1_120_hdr 0x3a 0x0 >,
		           < 0x3 0x0 &sdp_k1_120_hdr 0x4c 0x0 >,
		           < 0x4 0x0 &sdp_k1_120_hdr 0x22 0x0 >,
		           < 0x5 0x0 &sdp_k1_120_hdr 0x4b 0x0 >,
		           < 0x6 0x0 &sdp_k1_120_hdr 0x2e 0x0 >,
		           < 0x7 0x0 &sdp_k1_120_hdr 0x49 0x0 >; /* in zephyr/boards/adi/sdp_k1/adi_sdp_120pin_connector.dtsi:84 */
		status = "disabled";                             /* in zephyr/boards/adi/sdp_k1/adi_sdp_120pin_connector.dtsi:92 */
	};

	/* node '/leds' defined in zephyr/boards/adi/sdp_k1/adi_sdp_k1.dts:25 */
	leds {
		compatible = "gpio-leds"; /* in zephyr/boards/adi/sdp_k1/adi_sdp_k1.dts:26 */

		/* node '/leds/led_ds3' defined in zephyr/boards/adi/sdp_k1/adi_sdp_k1.dts:28 */
		status_led: led_ds3 {
			gpios = < &gpiok 0x4 0x0 >; /* in zephyr/boards/adi/sdp_k1/adi_sdp_k1.dts:29 */
			label = "Status DS3";       /* in zephyr/boards/adi/sdp_k1/adi_sdp_k1.dts:30 */
		};

		/* node '/leds/led_ds4' defined in zephyr/boards/adi/sdp_k1/adi_sdp_k1.dts:33 */
		green_led_1: led_ds4 {
			gpios = < &gpiok 0x5 0x0 >; /* in zephyr/boards/adi/sdp_k1/adi_sdp_k1.dts:34 */
			label = "User LD1";         /* in zephyr/boards/adi/sdp_k1/adi_sdp_k1.dts:35 */
		};

		/* node '/leds/led_ds5' defined in zephyr/boards/adi/sdp_k1/adi_sdp_k1.dts:38 */
		orange_led_2: led_ds5 {
			gpios = < &gpiok 0x6 0x0 >; /* in zephyr/boards/adi/sdp_k1/adi_sdp_k1.dts:39 */
			label = "User LD2";         /* in zephyr/boards/adi/sdp_k1/adi_sdp_k1.dts:40 */
		};

		/* node '/leds/led_ds6' defined in zephyr/boards/adi/sdp_k1/adi_sdp_k1.dts:43 */
		red_led_3: led_ds6 {
			gpios = < &gpiok 0x7 0x0 >; /* in zephyr/boards/adi/sdp_k1/adi_sdp_k1.dts:44 */
			label = "User LD3";         /* in zephyr/boards/adi/sdp_k1/adi_sdp_k1.dts:45 */
		};
	};

	/* node '/otghs_ulpis_phy' defined in zephyr/boards/adi/sdp_k1/adi_sdp_k1.dts:49 */
	otghs_ulpi_phy: otghs_ulpis_phy {
		compatible = "usb-ulpi-phy";      /* in zephyr/boards/adi/sdp_k1/adi_sdp_k1.dts:50 */
		reset-gpios = < &gpiod 0x7 0x1 >; /* in zephyr/boards/adi/sdp_k1/adi_sdp_k1.dts:51 */
		#phy-cells = < 0x0 >;             /* in zephyr/boards/adi/sdp_k1/adi_sdp_k1.dts:52 */
		phandle = < 0x15 >;               /* in zephyr/boards/adi/sdp_k1/adi_sdp_k1.dts:111 */
	};
};
